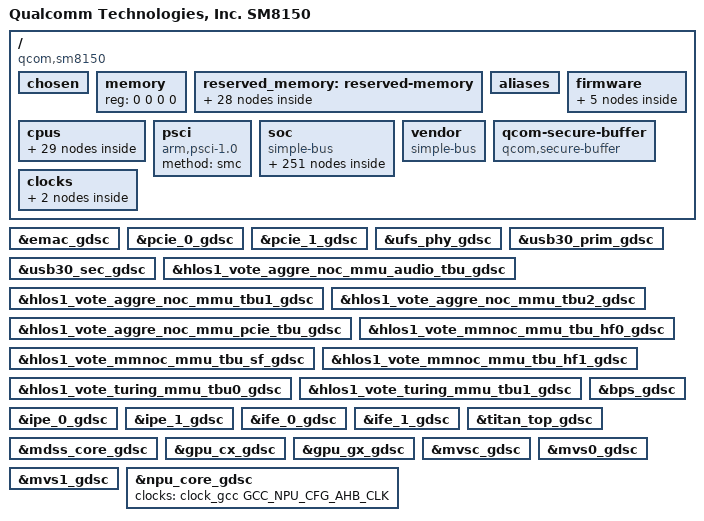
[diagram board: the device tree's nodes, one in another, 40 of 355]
// SPDX-License-Identifier: GPL-2.0-only
/*
 * Copyright (c) 2017-2020, The Linux Foundation. All rights reserved.
 */

#include <dt-bindings/clock/qcom,gcc-sm8150.h>
#include <dt-bindings/clock/qcom,camcc-sm8150.h>
#include <dt-bindings/clock/qcom,dispcc-sm8150.h>
#include <dt-bindings/clock/qcom,gpucc-sm8150.h>
#include <dt-bindings/clock/qcom,scc-sm8150.h>
#include <dt-bindings/clock/qcom,videocc-sm8150.h>
#include <dt-bindings/interconnect/qcom,icc.h>
#include <dt-bindings/interconnect/qcom,osm-l3.h>
#include <dt-bindings/interconnect/qcom,sm8150.h>
#include <dt-bindings/clock/qcom,npucc-sm8150.h>
#include <dt-bindings/gpio/gpio.h>
#include <dt-bindings/clock/qcom,rpmh.h>
#include <dt-bindings/sound/qcom,gpr.h>
#include <dt-bindings/clock/qcom,aop-qmp.h>
#include <dt-bindings/regulator/qcom,rpmh-regulator-levels.h>
#include <dt-bindings/interrupt-controller/arm-gic.h>
#include <dt-bindings/soc/qcom,rpmh-rsc.h>
#include <dt-bindings/soc/qcom,dcc_v2.h>
#include <dt-bindings/spmi/spmi.h>

#define MHZ_TO_MBPS(mhz, w) ((mhz * 1000000 * w) / (1024 * 1024))
#define BW_OPP_ENTRY(mhz, w) opp-mhz {opp-hz = /bits/ 64 <MHZ_TO_MBPS(mhz, w)>;}
#define BW_OPP_ENTRY_DDR(mhz, w, ddrtype) opp-mhz {\
				opp-hz = /bits/ 64 <MHZ_TO_MBPS(mhz, w)>;\
				opp-supported-hw = <ddrtype>;}

/ {
	model = "Qualcomm Technologies, Inc. SM8150";
	compatible = "qcom,sm8150";
	qcom,msm-name = "SM8150 V1";
	qcom,msm-id = <339 0x10000>;
	interrupt-parent = <&intc>;

	#address-cells = <2>;
	#size-cells = <2>;

	chosen: chosen {
		bootargs = "rcupdate.rcu_expedited=1 rcu_nocbs=0-7 cgroup.memory=nokmem,nosocket kpti=0 ssbd=force-off";
	};

	memory { device_type = "memory"; reg = <0 0 0 0>; };
	reserved_memory: reserved-memory { };

	aliases {
		ufshc1 = &ufshc_mem; /* Embedded UFS slot */
		sdhc2 = &sdhc_2; /* SDC2 SD card slot */
		pci-domain0 = &pcie0; /* PCIe0 domain */
		pci-domain1 = &pcie1; /* PCIe1 domain */
		mhi0 = &mhi_0;
		mhi1 = &mhi_1;
		mhi-netdev0 = &mhi_netdev_0;
		mhi-netdev2 = &mhi_netdev_2;
		serial0 = &qupv3_se12_2uart;
		hsuart0 = &qupv3_se13_4uart;
		hsuart1 = &qupv3_se4_2uart;
		spi0 = &qupv3_se3_spi;
		spi1 = &qupv3_se1_spi;
		i2c0 = &qupv3_se4_i2c;
	};

	firmware: firmware { };

	cpus {
		#address-cells = <2>;
		#size-cells = <0>;

		CPU0: cpu@0 {
			device_type = "cpu";
			compatible = "arm,armv8";
			reg = <0x0 0x0>;
			enable-method = "psci";
			qcom,freq-domain = <&cpufreq_hw 0 4>;
			capacity-dmips-mhz = <488>;
			dynamic-power-coefficient = <232>;
			cpu-idle-states = <&SLVR_RAIL_OFF>;
			next-level-cache = <&L2_0>;
			qcom,lmh-dcvs = <&lmh_dcvs0>;
			#cooling-cells = <2>;
			L2_0: l2-cache {
			      compatible = "arm,arch-cache";
			      cache-level = <2>;
			      next-level-cache = <&L3_0>;

				L3_0: l3-cache {
				      compatible = "arm,arch-cache";
				      cache-level = <3>;
				};
			};
		};

		CPU1: cpu@100 {
			device_type = "cpu";
			compatible = "arm,armv8";
			reg = <0x0 0x100>;
			enable-method = "psci";
			qcom,freq-domain = <&cpufreq_hw 0 4>;
			capacity-dmips-mhz = <488>;
			dynamic-power-coefficient = <232>;
			cpu-idle-states = <&SLVR_RAIL_OFF>;
			next-level-cache = <&L2_1>;
			qcom,lmh-dcvs = <&lmh_dcvs0>;
			#cooling-cells = <2>;
			L2_1: l2-cache {
			      compatible = "arm,arch-cache";
			      cache-level = <2>;
			      next-level-cache = <&L3_0>;
			};
		};

		CPU2: cpu@200 {
			device_type = "cpu";
			compatible = "arm,armv8";
			reg = <0x0 0x200>;
			enable-method = "psci";
			qcom,freq-domain = <&cpufreq_hw 0 4>;
			capacity-dmips-mhz = <488>;
			dynamic-power-coefficient = <232>;
			cpu-idle-states = <&SLVR_RAIL_OFF>;
			next-level-cache = <&L2_2>;
			qcom,lmh-dcvs = <&lmh_dcvs0>;
			#cooling-cells = <2>;
			L2_2: l2-cache {
			      compatible = "arm,arch-cache";
			      cache-level = <2>;
			      next-level-cache = <&L3_0>;
			};
		};

		CPU3: cpu@300 {
			device_type = "cpu";
			compatible = "arm,armv8";
			reg = <0x0 0x300>;
			enable-method = "psci";
			qcom,freq-domain = <&cpufreq_hw 0 4>;
			capacity-dmips-mhz = <488>;
			dynamic-power-coefficient = <232>;
			cpu-idle-states = <&SLVR_RAIL_OFF>;
			next-level-cache = <&L2_3>;
			qcom,lmh-dcvs = <&lmh_dcvs0>;
			#cooling-cells = <2>;
			L2_3: l2-cache {
			      compatible = "arm,arch-cache";
			      cache-level = <2>;
			      next-level-cache = <&L3_0>;
			};
		};

		CPU4: cpu@400 {
			device_type = "cpu";
			compatible = "arm,armv8";
			reg = <0x0 0x400>;
			enable-method = "psci";
			qcom,freq-domain = <&cpufreq_hw 1 4>;
			capacity-dmips-mhz = <1024>;
			dynamic-power-coefficient = <369>;
			cpu-idle-states = <&GOLD_RAIL_OFF>;
			next-level-cache = <&L2_4>;
			qcom,lmh-dcvs = <&lmh_dcvs1>;
			#cooling-cells = <2>;
			L2_4: l2-cache {
			      compatible = "arm,arch-cache";
			      cache-level = <2>;
			      next-level-cache = <&L3_0>;
			};
		};

		CPU5: cpu@500 {
			device_type = "cpu";
			compatible = "arm,armv8";
			reg = <0x0 0x500>;
			enable-method = "psci";
			qcom,freq-domain = <&cpufreq_hw 1 4>;
			capacity-dmips-mhz = <1024>;
			dynamic-power-coefficient = <369>;
			cpu-idle-states = <&GOLD_RAIL_OFF>;
			next-level-cache = <&L2_5>;
			qcom,lmh-dcvs = <&lmh_dcvs1>;
			#cooling-cells = <2>;
			L2_5: l2-cache {
			      compatible = "arm,arch-cache";
			      cache-level = <2>;
			      next-level-cache = <&L3_0>;
			};
		};

		CPU6: cpu@600 {
			device_type = "cpu";
			compatible = "arm,armv8";
			reg = <0x0 0x600>;
			enable-method = "psci";
			qcom,freq-domain = <&cpufreq_hw 1 4>;
			capacity-dmips-mhz = <1024>;
			dynamic-power-coefficient = <369>;
			cpu-idle-states = <&GOLD_RAIL_OFF>;
			next-level-cache = <&L2_6>;
			qcom,lmh-dcvs = <&lmh_dcvs1>;
			#cooling-cells = <2>;
			L2_6: l2-cache {
			      compatible = "arm,arch-cache";
			      cache-level = <2>;
			      next-level-cache = <&L3_0>;
			};
		};

		CPU7: cpu@700 {
			device_type = "cpu";
			compatible = "arm,armv8";
			reg = <0x0 0x700>;
			enable-method = "psci";
			qcom,freq-domain = <&cpufreq_hw 2 4>;
			capacity-dmips-mhz = <1024>;
			dynamic-power-coefficient = <421>;
			cpu-idle-states = <&GOLD_RAIL_OFF>;
			next-level-cache = <&L2_7>;
			qcom,lmh-dcvs = <&lmh_dcvs1>;
			#cooling-cells = <2>;
			L2_7: l2-cache {
			      compatible = "arm,arch-cache";
			      cache-level = <2>;
			      next-level-cache = <&L3_0>;
			};
		};

		cpu-map {
			cluster0 {
				core0 {
					cpu = <&CPU0>;
				};

				core1 {
					cpu = <&CPU1>;
				};

				core2 {
					cpu = <&CPU2>;
				};

				core3 {
					cpu = <&CPU3>;
				};
			};

			cluster1 {
				core0 {
					cpu = <&CPU4>;
				};

				core1 {
					cpu = <&CPU5>;
				};

				core2 {
					cpu = <&CPU6>;
				};
			};

			cluster2 {
				core0 {
					cpu = <&CPU7>;
				};
			};
		};
	};

	psci {
		compatible = "arm,psci-1.0";
		method = "smc";
	};

	soc: soc { };

	vendor: vendor {
		#address-cells = <1>;
		#size-cells = <1>;
		ranges = <0 0 0 0xffffffff>;
		compatible = "simple-bus";
	};

	qcom-secure-buffer {
		compatible = "qcom,secure-buffer";
	};

	clocks {
		xo_board: xo-board {
			compatible = "fixed-clock";
			clock-frequency = <38400000>;
			clock-output-names = "xo_board";
			#clock-cells = <0>;
		};

		sleep_clk: sleep-clk {
			compatible = "fixed-clock";
			clock-frequency = <32764>;
			clock-output-names = "sleep_clk";
			#clock-cells = <0>;
		};
	};
};

&firmware {
	scm {
		compatible = "qcom,scm";
	};
	android {
		compatible = "android,firmware";
		shared_meta: vbmeta {
			compatible = "android,vbmeta";
			parts = "vbmeta,boot,system,vendor,dtbo";
		};
		android_q_fstab: fstab {
			compatible = "android,fstab";
			vendor {
				compatible = "android,vendor";
				dev = "/dev/block/platform/soc/8804000.ufshc/by-name/vendor";
				type = "ext4";
				mnt_flags = "ro,barrier=1,discard";
				fsmgr_flags = "wait";
				status = "ok";
			};
		};
	};
};

&reserved_memory {
	#address-cells = <2>;
	#size-cells = <2>;
	ranges;

	hyp_mem: hyp_mem {
		no-map;
		reg = <0x0 0x85700000 0x0 0x600000>;
	};

	xbl_aop_mem: xbl_aop_mem {
		no-map;
		reg = <0x0 0x85e00000 0x0 0x120000>;
	};

	cmd_db: reserved-memory@85f20000 {
		compatible = "qcom,cmd-db";
		reg = <0x0 0x85f20000 0x0 0x20000>;
		no-map;
	};

	smem_region: smem {
		no-map;
		reg = <0x0 0x86000000 0x0 0x200000>;
	};

	removed_regions: removed_regions {
		no-map;
		reg = <0x0 0x86200000 0x0 0x5500000>;
	};

	pil_camera_mem: camera_region {
		compatible = "removed-dma-pool";
		no-map;
		reg = <0x0 0x8b700000 0x0 0x500000>;
	};

	pil_wlan_fw_mem: pil_wlan_fw_region {
		compatible = "removed-dma-pool";
		no-map;
		reg = <0x0 0x8bc00000 0x0 0x180000>;
	};

	pil_npu_mem: pil_npu_region {
		compatible = "removed-dma-pool";
		no-map;
		reg = <0x0 0x8bd80000 0x0 0x80000>;
	};

	pil_adsp_mem: pil_adsp_region {
		compatible = "removed-dma-pool";
		no-map;
		reg = <0x0 0x8be00000 0x0 0x2200000>;
	};

	pil_modem_mem: modem_region {
		compatible = "removed-dma-pool";
		no-map;
		reg = <0x0 0x8e000000 0x0 0x9600000>;
	};

	pil_video_mem: pil_video_region {
		compatible = "removed-dma-pool";
		no-map;
		reg = <0x0 0x97600000 0x0 0x500000>;
	};

	pil_slpi_mem: pil_slpi_region {
		compatible = "removed-dma-pool";
		no-map;
		reg = <0x0 0x97b00000 0x0 0x1400000>;
	};

	pil_ipa_fw_mem: pil_ipa_fw_region {
		compatible = "removed-dma-pool";
		no-map;
		reg = <0x0 0x98f00000 0x0 0x10000>;
	};

	pil_ipa_gsi_mem: pil_ipa_gsi_region {
		compatible = "removed-dma-pool";
		no-map;
		reg = <0x0 0x98f10000 0x0 0x5000>;
	};

	pil_gpu_mem: pil_gpu_region {
		compatible = "removed-dma-pool";
		no-map;
		reg = <0x0 0x98f15000 0x0 0x2000>;
	};

	pil_spss_mem: pil_spss_region {
		compatible = "removed-dma-pool";
		no-map;
		reg = <0x0 0x99000000 0x0 0x100000>;
	};

	pil_cdsp_mem: cdsp_regions {
		compatible = "removed-dma-pool";
		no-map;
		reg = <0x0 0x99100000 0x0 0x1400000>;
	};

	qseecom_mem: qseecom_region {
		compatible = "shared-dma-pool";
		no-map;
		reg = <0 0x9e400000 0 0x1400000>;
	};

	cdsp_sec_mem: cdsp_sec_regions {
		compatible = "removed-dma-pool";
		no-map;
		reg = <0x0 0xa4c00000 0x0 0x3c00000>;
	};

	cont_splash_memory: splash_region {
		reg = <0x0 0x9c000000 0x0 0x02400000>;
		label = "cont_splash_region";
	};

	dfps_data_memory: dfps_data_memory {
		reg = <0x0 0xe3300000 0x0 0x0100000>;
		label = "dfps_data_memory";
	};

	adsp_mem: adsp_region {
		compatible = "shared-dma-pool";
		alloc-ranges = <0x0 0x00000000 0x0 0xffffffff>;
		reusable;
		alignment = <0x0 0x400000>;
		size = <0x0 0x1000000>;
	};

	cdsp_mem: cdsp_region {
		compatible = "shared-dma-pool";
		alloc-ranges = <0x0 0x00000000 0x0 0xffffffff>;
		reusable;
		alignment = <0x0 0x400000>;
		size = <0x0 0x400000>;
	};

	user_contig_mem: user_contig_region {
		compatible = "shared-dma-pool";
		alloc-ranges = <0x0 0x00000000 0x0 0xffffffff>;
		reusable;
		alignment = <0x0 0x400000>;
		size = <0x0 0x1000000>;
	};

	qseecom_ta_mem: qseecom_ta_region {
		compatible = "shared-dma-pool";
		alloc-ranges = <0x0 0x00000000 0x0 0xffffffff>;
		reusable;
		alignment = <0x0 0x400000>;
		size = <0x0 0x1000000>;
	};

	sp_mem: sp_region {  /* SPSS-HLOS ION shared mem */
		compatible = "shared-dma-pool";
		alloc-ranges = <0x0 0x00000000 0x0 0xffffffff>;
		reusable;
		alignment = <0x0 0x400000>;
		size = <0x0 0x800000>;
	};

	secure_display_memory: secure_display_region { /* Secure UI */
		compatible = "shared-dma-pool";
		alloc-ranges = <0x0 0x00000000 0x0 0xffffffff>;
		reusable;
		alignment = <0x0 0x400000>;
		size = <0x0 0xA000000>;
	};

	/* global autoconfigured region for contiguous allocations */
	linux,cma {
		compatible = "shared-dma-pool";
		alloc-ranges = <0x0 0x00000000 0x0 0xffffffff>;
		reusable;
		alignment = <0x0 0x400000>;
		size = <0x0 0x2800000>;
		linux,cma-default;
	};
};

#include "sm8150-gdsc.dtsi"

#include "sm8150-sde.dtsi"
#include "msm-rdbg.dtsi"

#include "sm8150-camera.dtsi"

#include "msm-qvr-external.dtsi"

&soc {
	#address-cells = <1>;
	#size-cells = <1>;
	ranges = <0 0 0 0xffffffff>;
	compatible = "simple-bus";

	spss_utils: qcom,spss_utils {
		compatible = "qcom,spss-utils";
		/* spss fuses physical address */
		qcom,spss-fuse1-addr = <0x007841c4>;
		qcom,spss-fuse1-bit = <27>;
		qcom,spss-fuse2-addr = <0x007841c4>;
		qcom,spss-fuse2-bit = <26>;
		qcom,spss-dev-firmware-name  = "spss1d";  /* 8 chars max */
		qcom,spss-test-firmware-name = "spss1t";  /* 8 chars max */
		qcom,spss-prod-firmware-name = "spss1p";  /* 8 chars max */
		qcom,spss-debug-reg-addr = <0x01886020>;
		qcom,spss-emul-type-reg-addr = <0x01fc8004>;
		qcom,no-cmac-and-iar-feature-support;
		status = "ok";
	};

	qcom,spcom {
		compatible = "qcom,spcom";

		/* predefined channels, remote side is server */
		qcom,spcom-ch-names = "sp_kernel", "sp_ssr";
		status = "ok";
	};

	jtag_mm0: jtagmm@7040000 {
		compatible = "qcom,jtagv8-mm";
		reg = <0x7040000 0x1000>;
		reg-names = "etm-base";

		clocks = <&clock_aop QDSS_CLK>;
		clock-names = "core_clk";

		qcom,coresight-jtagmm-cpu = <&CPU0>;
		status = "disabled";
	};

	jtag_mm1: jtagmm@7140000 {
		compatible = "qcom,jtagv8-mm";
		reg = <0x7140000 0x1000>;
		reg-names = "etm-base";

		clocks = <&clock_aop QDSS_CLK>;
		clock-names = "core_clk";

		qcom,coresight-jtagmm-cpu = <&CPU1>;
		status = "disabled";
	};

	jtag_mm2: jtagmm@7240000 {
		compatible = "qcom,jtagv8-mm";
		reg = <0x7240000 0x1000>;
		reg-names = "etm-base";

		clocks = <&clock_aop QDSS_CLK>;
		clock-names = "core_clk";

		qcom,coresight-jtagmm-cpu = <&CPU2>;
		status = "disabled";
	};

	jtag_mm3: jtagmm@7340000 {
		compatible = "qcom,jtagv8-mm";
		reg = <0x7340000 0x1000>;
		reg-names = "etm-base";

		clocks = <&clock_aop QDSS_CLK>;
		clock-names = "core_clk";

		qcom,coresight-jtagmm-cpu = <&CPU3>;
		status = "disabled";
	};

	jtag_mm4: jtagmm@7440000 {
		compatible = "qcom,jtagv8-mm";
		reg = <0x7440000 0x1000>;
		reg-names = "etm-base";

		clocks = <&clock_aop QDSS_CLK>;
		clock-names = "core_clk";

		qcom,coresight-jtagmm-cpu = <&CPU4>;
		status = "disabled";
	};

	jtag_mm5: jtagmm@7540000 {
		compatible = "qcom,jtagv8-mm";
		reg = <0x7540000 0x1000>;
		reg-names = "etm-base";

		clocks = <&clock_aop QDSS_CLK>;
		clock-names = "core_clk";

		qcom,coresight-jtagmm-cpu = <&CPU5>;
		status = "disabled";
	};

	jtag_mm6: jtagmm@7640000 {
		compatible = "qcom,jtagv8-mm";
		reg = <0x7640000 0x1000>;
		reg-names = "etm-base";

		clocks = <&clock_aop QDSS_CLK>;
		clock-names = "core_clk";

		qcom,coresight-jtagmm-cpu = <&CPU6>;
		status = "disabled";
	};

	jtag_mm7: jtagmm@7740000 {
		compatible = "qcom,jtagv8-mm";
		reg = <0x7740000 0x1000>;
		reg-names = "etm-base";

		clocks = <&clock_aop QDSS_CLK>;
		clock-names = "core_clk";

		qcom,coresight-jtagmm-cpu = <&CPU7>;
		status = "disabled";
	};

	intc: interrupt-controller@17a00000 {
		compatible = "arm,gic-v3";
		#interrupt-cells = <3>;
		interrupt-controller;
		#redistributor-regions = <1>;
		redistributor-stride = <0x0 0x20000>;
		reg = <0x17a00000 0x10000>,     /* GICD */
		      <0x17a60000 0x100000>;    /* GICR * 8 */
		interrupts = <GIC_PPI 9 IRQ_TYPE_LEVEL_HIGH>;
		interrupt-parent = <&intc>;
	};

	gict: gict@17a20000 {
		compatible = "arm,gic-600-erp";
		reg = <0x17a20000 0x10000>;
		reg-names = "gict-base";
		interrupt-config = <46 17>;
		interrupt-names = "gict-fault", "gict-err";
		interrupts = <GIC_SPI 46 IRQ_TYPE_LEVEL_HIGH>,
			     <GIC_SPI 17 IRQ_TYPE_LEVEL_HIGH>;
	};

	pdc: interrupt-controller@b220000 {
		compatible = "qcom,sm8150-pdc";
		reg = <0xb220000 0x400>;
		qcom,pdc-ranges = <0 480 94>, <94 609 31>, <125 63 1>;
		#interrupt-cells = <2>;
		interrupt-parent = <&intc>;
		interrupt-controller;
	};

	timer {
		compatible = "arm,armv8-timer";
		interrupts = <GIC_PPI 1 (GIC_CPU_MASK_SIMPLE(8) | IRQ_TYPE_LEVEL_LOW)>,
			     <GIC_PPI 2 (GIC_CPU_MASK_SIMPLE(8) | IRQ_TYPE_LEVEL_LOW)>,
			     <GIC_PPI 3 (GIC_CPU_MASK_SIMPLE(8) | IRQ_TYPE_LEVEL_LOW)>,
			     <GIC_PPI 0 (GIC_CPU_MASK_SIMPLE(8) | IRQ_TYPE_LEVEL_LOW)>;
		clock-frequency = <19200000>;
	};

	timer@17c20000{
		#address-cells = <1>;
		#size-cells = <1>;
		ranges;
		compatible = "arm,armv7-timer-mem";
		reg = <0x17c20000 0x1000>;
		clock-frequency = <19200000>;

		frame@17c21000 {
			frame-number = <0>;
			interrupts = <GIC_SPI 8 IRQ_TYPE_LEVEL_HIGH>,
				     <GIC_SPI 6 IRQ_TYPE_LEVEL_HIGH>;
			reg = <0x17c21000 0x1000>,
			      <0x17c22000 0x1000>;
		};

		frame@17c23000 {
			frame-number = <1>;
			interrupts = <GIC_SPI 9 IRQ_TYPE_LEVEL_HIGH>;
			reg = <0x17c23000 0x1000>;
			status = "disabled";
		};

		frame@17c25000 {
			frame-number = <2>;
			interrupts = <GIC_SPI 10 IRQ_TYPE_LEVEL_HIGH>;
			reg = <0x17c25000 0x1000>;
			status = "disabled";
		};

		frame@17c27000 {
			frame-number = <3>;
			interrupts = <GIC_SPI 11 IRQ_TYPE_LEVEL_HIGH>;
			reg = <0x17c26000 0x1000>;
			status = "disabled";
		};

		frame@17c29000 {
			frame-number = <4>;
			interrupts = <GIC_SPI 12 IRQ_TYPE_LEVEL_HIGH>;
			reg = <0x17c29000 0x1000>;
			status = "disabled";
		};

		frame@17c2b000 {
			frame-number = <5>;
			interrupts = <GIC_SPI 13 IRQ_TYPE_LEVEL_HIGH>;
			reg = <0x17c2b000 0x1000>;
			status = "disabled";
		};

		frame@17c2d000 {
			frame-number = <6>;
			interrupts = <GIC_SPI 14 IRQ_TYPE_LEVEL_HIGH>;
			reg = <0x17c2d000 0x1000>;
			status = "disabled";
		};
	};

	llcc_pmu: llcc-pmu@90cc000 {
		compatible = "qcom,llcc-pmu-ver1";
		reg = <0x090cc000 0x300>;
		reg-names = "lagg-base";
	};

	llcc_bw_opp_table: llcc-bw-opp-table {
		compatible = "operating-points-v2";
		BW_OPP_ENTRY(150, 16); /*  2288 MB/s */
		BW_OPP_ENTRY(200, 16); /*  3051 MB/s */
		BW_OPP_ENTRY(403, 16); /*  6149 MB/s */
		BW_OPP_ENTRY(533, 16); /*  8132 MB/s */
		BW_OPP_ENTRY(666, 16); /* 10162 MB/s */
		BW_OPP_ENTRY(777, 16); /* 11856 MB/s */
	};

	ddr_bw_opp_table: ddr-bw-opp-table {
		compatible = "operating-points-v2";
		BW_OPP_ENTRY_DDR( 200, 4, 0x80); /*  762 MB/s */
		BW_OPP_ENTRY_DDR( 300, 4, 0x80); /* 1144 MB/s */
		BW_OPP_ENTRY_DDR( 451, 4, 0x80); /* 1720 MB/s */
		BW_OPP_ENTRY_DDR( 547, 4, 0x80); /* 2086 MB/s */
		BW_OPP_ENTRY_DDR( 681, 4, 0x80); /* 2597 MB/s */
		BW_OPP_ENTRY_DDR( 768, 4, 0x80); /* 2929 MB/s */
		BW_OPP_ENTRY_DDR(1017, 4, 0x80); /* 3879 MB/s */
		BW_OPP_ENTRY_DDR(1296, 4, 0x80); /* 4943 MB/s */
		BW_OPP_ENTRY_DDR(1555, 4, 0x80); /* 5931 MB/s */
		BW_OPP_ENTRY_DDR(1804, 4, 0x80); /* 6881 MB/s */
		BW_OPP_ENTRY_DDR(2092, 4, 0x80); /* 7980 MB/s */
	};

	cpu_cpu_llcc_bw: qcom,cpu-cpu-llcc-bw {
		compatible = "qcom,devfreq-icc";
		governor = "bw_hwmon";
		interconnects = <&gem_noc MASTER_APPSS_PROC
				&gem_noc SLAVE_LLCC>;
		qcom,active-only;
		operating-points-v2 = <&llcc_bw_opp_table>;
	};

	cpu_cpu_llcc_bwmon: qcom,cpu-cpu-llcc-bwmon@90b6400 {
		compatible = "qcom,bimc-bwmon4";
		reg = <0x90b6400 0x300>, <0x90b6300 0x200>;
		reg-names = "base", "global_base";
		interrupts = <GIC_SPI 581 IRQ_TYPE_LEVEL_HIGH>;
		qcom,mport = <0>;
		qcom,hw-timer-hz = <19200000>;
		qcom,target-dev = <&cpu_cpu_llcc_bw>;
		qcom,count-unit = <0x10000>;
	};

	cpu_llcc_ddr_bw: qcom,cpu-llcc-ddr-bw {
		compatible = "qcom,devfreq-icc-ddr";
		governor = "bw_hwmon";
		interconnects = <&mc_virt MASTER_LLCC &mc_virt SLAVE_EBI1>;
		qcom,active-only;
		operating-points-v2 = <&ddr_bw_opp_table>;
	};

	cpu_llcc_ddr_bwmon: qcom,cpu-llcc-ddr-bwmon@90cd000 {
		compatible = "qcom,bimc-bwmon5";
		reg = <0x90cd000 0x1000>;
		reg-names = "base";
		interrupts = <GIC_SPI 81 IRQ_TYPE_LEVEL_HIGH>;
		qcom,hw-timer-hz = <19200000>;
		qcom,target-dev = <&cpu_llcc_ddr_bw>;
		qcom,count-unit = <0x10000>;
	};

	cpu0_cpu_l3_lat: qcom,cpu0-cpu-l3-lat {
		compatible = "qcom,devfreq-icc-l3";
		reg = <0x18321110 0x500>;
		reg-names = "ftbl-base";
		qcom,ftbl-row-size = <0x20>;
		governor = "mem_latency";
		interconnects = <&osm_l3 MASTER_OSM_L3_APPS
				&osm_l3 SLAVE_OSM_L3_CLUSTER0>;
	};

	cpu0_cpu_l3_tbl: qcom,cpu0-cpu-l3-tbl {
		qcom,core-dev-table =
			<  300000  300000000 >,
			<  480000  403200000 >,
			<  672000  480000000 >,
			<  768000  576000000 >,
			<  864000  672000000 >,
			<  979200  768000000 >,
			< 1075200  864000000 >,
			< 1267200  960000000 >;
	};

	cpu0_cpu_llcc_lat: qcom,cpu0-cpu-llcc-lat {
		compatible = "qcom,devfreq-icc";
		governor = "mem_latency";
		interconnects = <&gem_noc MASTER_APPSS_PROC
				&gem_noc SLAVE_LLCC>;
		qcom,active-only;
		operating-points-v2 = <&llcc_bw_opp_table>;
	};

	cpu0_llcc_ddr_lat: qcom,cpu0-llcc-ddr-lat {
		compatible = "qcom,devfreq-icc-ddr";
		governor = "mem_latency";
		interconnects = <&mc_virt MASTER_LLCC &mc_virt SLAVE_EBI1>;
		qcom,active-only;
		operating-points-v2 = <&ddr_bw_opp_table>;
	};

	cpu0_memlat_cpugrp: qcom,cpu0-cpugrp {
		compatible = "qcom,arm-memlat-cpugrp";
		qcom,cpulist = <&CPU0 &CPU1 &CPU2 &CPU3>;

		cpu0_cpu_l3_latmon: qcom,cpu0-cpu-l3-latmon {
			compatible = "qcom,arm-memlat-mon";
			qcom,cpulist = <&CPU0 &CPU1 &CPU2 &CPU3>;
			qcom,target-dev = <&cpu0_cpu_l3_lat>;
			qcom,cachemiss-ev = <0x17>;
			qcom,core-dev-table = <&cpu0_cpu_l3_tbl>;
		};

		cpu0_cpu_llcc_latmon: qcom,cpu0-cpu-llcc-latmon {
			compatible = "qcom,arm-memlat-mon";
			qcom,cpulist = <&CPU0 &CPU1 &CPU2 &CPU3>;
			qcom,target-dev = <&cpu0_cpu_llcc_lat>;
			qcom,cachemiss-ev = <0x2A>;
			qcom,core-dev-table =
				<  300000 MHZ_TO_MBPS(150, 16) >,
				<  768000 MHZ_TO_MBPS(200, 16) >,
				< 1075200 MHZ_TO_MBPS(403, 16) >,
				< 1267200 MHZ_TO_MBPS(403, 16) >;
		};

		cpu0_llcc_ddr_latmon: qcom,cpu0-llcc-ddr-latmon {
			compatible = "qcom,arm-memlat-mon";
			qcom,cpulist = <&CPU0 &CPU1 &CPU2 &CPU3>;
			qcom,target-dev = <&cpu0_llcc_ddr_lat>;
			qcom,cachemiss-ev = <0x1000>;
			qcom,core-dev-table =
				<  300000 MHZ_TO_MBPS( 200, 4) >,
				<  768000 MHZ_TO_MBPS( 451, 4) >,
				< 1075200 MHZ_TO_MBPS( 547, 4) >,
				< 1267200 MHZ_TO_MBPS( 768, 4) >;
		};
	};

	cpu4_cpu_l3_lat: qcom,cpu4-cpu-l3-lat {
		compatible = "qcom,devfreq-icc-l3";
		reg = <0x18321110 0x500>;
		reg-names = "ftbl-base";
		qcom,ftbl-row-size = <0x20>;
		governor = "mem_latency";
		interconnects = <&osm_l3 MASTER_OSM_L3_APPS
				&osm_l3 SLAVE_OSM_L3_CLUSTER1>;
	};

	cpu4_cpu_l3_tbl: qcom,cpu4_cpu_l3_tbl {
		qcom,core-dev-table =
			<  300000  300000000 >,
			<  768000  576000000 >,
			< 1152000  768000000 >,
			< 1344000  960000000 >,
			< 1689600 1228800000 >,
			< 2016000 1344000000 >;
	};

	cpu4_cpu_llcc_lat: qcom,cpu4-cpu-llcc-lat {
		compatible = "qcom,devfreq-icc";
		governor = "mem_latency";
		interconnects = <&gem_noc MASTER_APPSS_PROC
				&gem_noc SLAVE_LLCC>;
		qcom,active-only;
		operating-points-v2 = <&llcc_bw_opp_table>;
	};

	cpu4_llcc_ddr_lat: qcom,cpu4-llcc-ddr-lat {
		compatible = "qcom,devfreq-icc-ddr";
		governor = "mem_latency";
		interconnects = <&mc_virt MASTER_LLCC &mc_virt SLAVE_EBI1>;
		qcom,active-only;
		operating-points-v2 = <&ddr_bw_opp_table>;
	};

	cpu4_cpu_ddr_latfloor: qcom,cpu4-cpu-ddr-latfloor {
		compatible = "qcom,devfreq-icc-ddr";
		governor = "compute";
		interconnects = <&mc_virt MASTER_LLCC &mc_virt SLAVE_EBI1>;
		qcom,active-only;
		operating-points-v2 = <&ddr_bw_opp_table>;
	};

	cdsp_cdsp_l3_lat: qcom,cdsp-cdsp-l3-lat {
		compatible = "qcom,devfreq-icc-l3";
		reg = <0x18321920 0x4>;
		reg-names = "perf-base";
		qcom,ftbl-row-size = <0x20>;
		governor = "powersave";
		interconnects = <&osm_l3 MASTER_OSM_L3_APPS
				&osm_l3 SLAVE_OSM_L3_MISC>;
	};

	cpu7_cpu_l3_lat: qcom,cpu7-cpu-l3-lat {
		compatible = "qcom,devfreq-icc-l3";
		reg = <0x18321110 0x500>;
		reg-names = "ftbl-base";
		qcom,ftbl-row-size = <0x20>;
		governor = "compute";
		interconnects = <&osm_l3 MASTER_OSM_L3_APPS
				&osm_l3 SLAVE_OSM_L3_CLUSTER2>;
	};

	cpu7_cpu_l3_tbl: qcom,cpu7_cpu_l3_tbl {
		qcom,core-dev-table =
			<  300000  300000000 >,
			<  768000  576000000 >,
			< 1152000  768000000 >,
			< 1344000  960000000 >,
			< 1689600 1228800000 >,
			< 2016000 1344000000 >;
	};

	cpu4_memlat_cpugrp: qcom,cpu4-cpugrp {
		compatible = "qcom,arm-memlat-cpugrp";
		qcom,cpulist = <&CPU4 &CPU5 &CPU6 &CPU7>;

		cpu4_cpu_l3_latmon: qcom,cpu4-cpu-l3-latmon {
			compatible = "qcom,arm-memlat-mon";
			qcom,cpulist = <&CPU4 &CPU5 &CPU6>;
			qcom,target-dev = <&cpu4_cpu_l3_lat>;
			qcom,cachemiss-ev = <0x17>;
			qcom,core-dev-table = <&cpu4_cpu_l3_tbl>;
		};

		cpu7_cpu_l3_latmon: qcom,cpu7-cpu-l3-latmon {
			compatible = "qcom,arm-memlat-mon";
			qcom,cpulist = <&CPU7>;
			qcom,target-dev = <&cpu7_cpu_l3_lat>;
			qcom,cachemiss-ev = <0x17>;
			qcom,core-dev-table = <&cpu7_cpu_l3_tbl>;
		};

		cpu4_cpu_llcc_latmon: qcom,cpu4-cpu-llcc-latmon {
			compatible = "qcom,arm-memlat-mon";
			qcom,cpulist = <&CPU4 &CPU5 &CPU6 &CPU7>;
			qcom,target-dev = <&cpu4_cpu_llcc_lat>;
			qcom,cachemiss-ev = <0x2A>;
			qcom,core-dev-table =
				<  300000 MHZ_TO_MBPS(150, 16) >,
				<  576000 MHZ_TO_MBPS(200, 16) >,
				<  768000 MHZ_TO_MBPS(403, 16) >,
				<  960000 MHZ_TO_MBPS(403, 16) >,
				< 1248000 MHZ_TO_MBPS(533, 16) >,
				< 1728000 MHZ_TO_MBPS(666, 16) >,
				< 2016000 MHZ_TO_MBPS(777, 16) >;
		};

		cpu4_llcc_ddr_latmon: qcom,cpu4-llcc-ddr-latmon {
			compatible = "qcom,arm-memlat-mon";
			qcom,cpulist = <&CPU4 &CPU5 &CPU6 &CPU7>;
			qcom,target-dev = <&cpu4_llcc_ddr_lat>;
			qcom,cachemiss-ev = <0x1000>;
			qcom,core-dev-table =
				<  300000 MHZ_TO_MBPS( 200, 4) >,
				<  576000 MHZ_TO_MBPS( 451, 4) >,
				<  768000 MHZ_TO_MBPS( 547, 4) >,
				<  960000 MHZ_TO_MBPS( 768, 4) >,
				< 1248000 MHZ_TO_MBPS(1017, 4) >,
				< 1728000 MHZ_TO_MBPS(1555, 4) >,
				< 2016000 MHZ_TO_MBPS(1804, 4) >,
				< 2054400 MHZ_TO_MBPS(2092, 4) >;
		};

		cpu4_computemon: qcom,cpu4-computemon {
			compatible = "qcom,arm-compute-mon";
			qcom,cpulist = <&CPU4 &CPU5 &CPU6 &CPU7>;
			qcom,target-dev = <&cpu4_cpu_ddr_latfloor>;
			qcom,core-dev-table =
				< 1593600 MHZ_TO_MBPS( 200, 4) >,
				< 2016000 MHZ_TO_MBPS(1017, 4) >,
				< 2054400 MHZ_TO_MBPS(2092, 4) >;
		};
	};

	npu_npu_ddr_bw: qcom,npu-npu-ddr-bw {
		compatible = "qcom,devfreq-icc-ddr";
		governor = "bw_hwmon";
		interconnects = <&compute_noc MASTER_NPU &mc_virt SLAVE_EBI1>;
		operating-points-v2 = <&ddr_bw_opp_table>;
	};

	npu_npu_ddr_bwmon: qcom,npu-npu-ddr-bwmon@9960300 {
		compatible = "qcom,bimc-bwmon4";
		reg = <0x9960300 0x300>, <0x9960200 0x200>;
		reg-names = "base", "global_base";
		interrupts = <GIC_SPI 365 IRQ_TYPE_LEVEL_HIGH>;
		qcom,mport = <0>;
		qcom,hw-timer-hz = <19200000>;
		qcom,target-dev = <&npu_npu_ddr_bw>;
		qcom,count-unit = <0x10000>;
	};

	cpu_pmu: cpu-pmu {
		compatible = "arm,armv8-pmuv3";
		qcom,irq-is-percpu;
		interrupts = <GIC_PPI 5 IRQ_TYPE_LEVEL_HIGH>;
	};

	qcom,msm-imem@146bf000 {
		compatible = "qcom,msm-imem";
		reg = <0x146bf000 0x1000>;
		ranges = <0x0 0x146bf000 0x1000>;
		#address-cells = <1>;
		#size-cells = <1>;

		mem_dump_table@10 {
			compatible = "qcom,msm-imem-mem_dump_table";
			reg = <0x10 8>;
		};

		restart_reason@65c {
			compatible = "qcom,msm-imem-restart_reason";
			reg = <0x65c 4>;
		};

		dload_type@1c {
			compatible = "qcom,msm-imem-dload-type";
			reg = <0x1c 0x4>;
		};

		boot_stats@6b0 {
			compatible = "qcom,msm-imem-boot_stats";
			reg = <0x6b0 32>;
		};

		kaslr_offset@6d0 {
			compatible = "qcom,msm-imem-kaslr_offset";
			reg = <0x6d0 12>;
		};

		pil@94c {
			compatible = "qcom,msm-imem-pil";
			reg = <0x94c 200>;
		};

		diag_dload@c8 {
			compatible = "qcom,msm-imem-diag-dload";
			reg = <0xc8 200>;
		};
	};

	restart@c264000 {
		compatible = "qcom,pshold";
		reg = <0xc264000 0x4>,
		      <0x1fd3000 0x4>;
		reg-names = "pshold-base", "tcsr-boot-misc-detect";
	};

	qcom,msm-rtb {
		compatible = "qcom,msm-rtb";
		qcom,rtb-size = <0x100000>;
	};

	pil_scm_pas {
		compatible = "qcom,pil-tz-scm-pas";
		interconnects = <&aggre2_noc MASTER_CRYPTO
				&mc_virt SLAVE_EBI1>;
	};

	qcom,aop-ddr-msgs {
		compatible = "qcom,aop-ddr-msgs";
		mboxes = <&qmp_aop 0>;
		mbox-name = "restart-ddr-mbox";
	};

	qcom,aop-ddrss-cmds {
		compatible = "qcom,aop-ddrss-cmds";
		mboxes = <&qmp_aop 0>;
		mbox-name = "ddrss-cmds-mbox";
	};

	qcom,mpm2-sleep-counter@c221000 {
		compatible = "qcom,mpm2-sleep-counter";
		reg = <0xc221000 0x1000>;
		clock-frequency = <32768>;
	};

	clock_aop: qcom,aopclk {
		compatible = "qcom,aop-qmp-clk";
		#clock-cells = <1>;
		mboxes = <&qmp_aop 0>;
		mbox-names = "qdss_clk";
	};

	clock_gcc: qcom,gcc {
		compatible = "qcom,gcc-sm8150", "syscon";
		reg = <0x100000 0x1f0000>;
		reg-names = "cc_base";
		vdd_cx-supply = <&VDD_CX_LEVEL>;
		vdd_cx_ao-supply = <&VDD_CX_LEVEL_AO>;
		vdd_mm-supply = <&VDD_MMCX_LEVEL>;
		#clock-cells = <1>;
		#reset-cells = <1>;
	};

	clock_videocc: qcom,videocc@ab00000 {
		compatible = "qcom,videocc-sm8150", "syscon";
		reg = <0xab00000 0x10000>;
		reg-names = "cc_base";
		vdd_mm-supply = <&VDD_MMCX_LEVEL>;
		clock-names = "cfg_ahb_clk";
		clocks = <&clock_gcc GCC_VIDEO_AHB_CLK>;
		#clock-cells = <1>;
		#reset-cells = <1>;
	};

	clock_camcc: qcom,camcc {
		compatible = "qcom,camcc-sm8150", "syscon";
		reg = <0xad00000 0x10000>;
		reg-names = "cc_base";
		vdd_mx-supply = <&VDD_MX_LEVEL>;
		vdd_mm-supply = <&VDD_MMCX_LEVEL>;
		clock-names = "cfg_ahb_clk";
		clocks = <&clock_gcc GCC_CAMERA_AHB_CLK>;

		qcom,cam_cc_csi0phytimer_clk_src-opp-handle = <&cam_csiphy0>;
		qcom,cam_cc_csi1phytimer_clk_src-opp-handle = <&cam_csiphy1>;
		qcom,cam_cc_csi2phytimer_clk_src-opp-handle = <&cam_csiphy2>;
		qcom,cam_cc_csi3phytimer_clk_src-opp-handle = <&cam_csiphy3>;
		qcom,cam_cc_cci_0_clk_src-opp-handle = <&cam_cci0>;
		qcom,cam_cc_cci_1_clk_src-opp-handle = <&cam_cci1>;
		qcom,cam_cc_ife_0_csid_clk_src-opp-handle = <&cam_csid0>;
		qcom,cam_cc_ife_0_clk_src-opp-handle = <&cam_vfe0>;
		qcom,cam_cc_ife_1_csid_clk_src-opp-handle = <&cam_csid1>;
		qcom,cam_cc_ife_1_clk_src-opp-handle = <&cam_vfe1>;
		qcom,cam_cc_ife_lite_0_csid_clk_src-opp-handle =
							<&cam_csid_lite0>;
		qcom,cam_cc_ife_lite_1_csid_clk_src-opp-handle =
							<&cam_csid_lite1>;
		qcom,cam_cc_ife_lite_0_clk_src-opp-handle = <&cam_vfe_lite0>;
		qcom,cam_cc_ife_lite_1_clk_src-opp-handle = <&cam_vfe_lite1>;
		qcom,cam_cc_icp_clk_src-opp-handle = <&cam_a5>;
		qcom,cam_cc_ipe_0_clk_src-opp-handle = <&cam_ipe0>;
		qcom,cam_cc_bps_clk_src-opp-handle = <&cam_bps>;

		#clock-cells = <1>;
	};

	clock_dispcc: qcom,dispcc {
		compatible = "qcom,dispcc-sm8150", "syscon";
		reg = <0xaf00000 0x20000>;
		reg-names = "cc_base";
		vdd_mm-supply = <&VDD_MMCX_LEVEL>;
		clock-names = "cfg_ahb_clk";
		clocks = <&clock_gcc GCC_DISP_AHB_CLK>;
		#clock-cells = <1>;
		#reset-cells = <1>;
	};

	clock_npucc: qcom,npucc {
		compatible = "qcom,npucc-sm8150", "syscon";
		reg = <0x9910000 0x10000>;
		reg-names = "cc_base";
		vdd_cx-supply = <&VDD_CX_LEVEL>;
		vdd_gdsc-supply = <&npu_core_gdsc>;
		#clock-cells = <1>;
		#reset-cells = <1>;
	};

	clock_gpucc: qcom,gpucc {
		compatible = "qcom,gpucc-sm8150", "syscon";
		reg = <0x2c90000 0x9000>;
		reg-names = "cc_base";
		vdd_cx-supply = <&VDD_CX_LEVEL>;
		vdd_mx-supply = <&VDD_MX_LEVEL>;
		qcom,gpu_cc_gmu_clk_src-opp-handle = <&gmu>;
		#clock-cells = <1>;
		#reset-cells = <1>;
	};

	clock_scc: qcom,scc@2b10000 {
		compatible = "qcom,scc-sm8150";
		reg = <0x2b10000 0x30000>;
		vdd_scc_cx-supply = <&pm8150_l8_level>;
		#clock-cells = <1>;
		status = "disabled";
	};

	cpucc_debug: syscon@182a0018 {
		compatible = "syscon";
		reg = <0x182a0018 0x4>;
	};

	mccc_debug: syscon@90b0000 {
		compatible = "syscon";
		reg = <0x90b0000 0x1000>;
	};

	clock_debugcc: qcom,cc-debug {
		compatible = "qcom,debugcc-sm8150";
		qcom,gcc = <&clock_gcc>;
		qcom,videocc = <&clock_videocc>;
		qcom,camcc = <&clock_camcc>;
		qcom,dispcc = <&clock_dispcc>;
		qcom,npucc = <&clock_npucc>;
		qcom,gpucc = <&clock_gpucc>;
		qcom,cpucc = <&cpucc_debug>;
		qcom,mccc = <&mccc_debug>;
		clock-names = "xo_clk_src";
		clocks = <&clock_rpmh RPMH_CXO_CLK>;
		#clock-cells = <1>;
	};

	cpufreq_hw: qcom,cpufreq-hw {
		compatible = "qcom,cpufreq-hw";
		reg = <0x18323000 0x1400>, <0x18325800 0x1400>,
		<0x18327800 0x1400>;
		reg-names = "freq-domain0", "freq-domain1",
		"freq-domain2";

		clocks = <&clock_rpmh RPMH_CXO_CLK>, <&clock_gcc GPLL0>;
		clock-names = "xo", "alternate";
		qcom,no-accumulative-counter;
		#freq-domain-cells = <2>;
	};

	qcom_clk_led: qcom_clk_led {
		compatible = "qcom,clk-led-pwm";
		qcom,label = "led_clk_gp2";
		clocks = <&clock_gcc GCC_GP2_CLK>;
		clock-names = "core";
		assigned-clocks = <&clock_gcc GCC_GP2_CLK>;
		assigned-clock-rates = <80000>;
		qcom,max_duty = <53>;
		pinctrl-names = "active", "sleep";
		pinctrl-0 = <&qcom_clk_led_gp2_active>;
		pinctrl-1 = <&qcom_clk_led_gp2_sleep>;
		status = "disabled";
	};

	spmi_bus: qcom,spmi@c440000 {
		compatible = "qcom,spmi-pmic-arb";
		reg = <0xc440000 0x1100>,
		      <0xc600000 0x2000000>,
		      <0xe600000 0x100000>,
		      <0xe700000 0xa0000>,
		      <0xc40a000 0x26000>;
		reg-names = "core", "chnls", "obsrvr", "intr", "cnfg";
		interrupt-names = "periph_irq";
		interrupts = <GIC_SPI 481 IRQ_TYPE_LEVEL_HIGH>;
		qcom,ee = <0>;
		qcom,channel = <0>;
		#address-cells = <2>;
		#size-cells = <0>;
		interrupt-controller;
		#interrupt-cells = <4>;
		cell-index = <0>;
	};

	spmi_debug_bus: qcom,spmi-debug@6b22000 {
		compatible = "qcom,spmi-pmic-arb-debug";
		reg = <0x6b22000 0x60>, <0x7820a8 4>;
		reg-names = "core", "fuse";
		clocks = <&clock_aop QDSS_CLK>;
		clock-names = "core_clk";
		qcom,fuse-disable-bit = <24>;
		#address-cells = <2>;
		#size-cells = <0>;
		status = "disabled";

		qcom,pm8150-debug@0 {
			compatible = "qcom,spmi-pmic";
			reg = <0x0 SPMI_USID>;
			#address-cells = <2>;
			#size-cells = <0>;
			qcom,can-sleep;
		};

		qcom,pm8150-debug@1 {
			compatible = "qcom,spmi-pmic";
			reg = <0x1 SPMI_USID>;
			#address-cells = <2>;
			#size-cells = <0>;
			qcom,can-sleep;
		};

		qcom,pm8150b-debug@2 {
			compatible = "qcom,spmi-pmic";
			reg = <0x2 SPMI_USID>;
			#address-cells = <2>;
			#size-cells = <0>;
			qcom,can-sleep;
		};

		qcom,pm8150b-debug@3 {
			compatible = "qcom,spmi-pmic";
			reg = <0x3 SPMI_USID>;
			#address-cells = <2>;
			#size-cells = <0>;
			qcom,can-sleep;
		};

		qcom,pm8150l-debug@4 {
			compatible = "qcom,spmi-pmic";
			reg = <0x4 SPMI_USID>;
			#address-cells = <2>;
			#size-cells = <0>;
			qcom,can-sleep;
		};

		qcom,pm8150l-debug@5 {
			compatible = "qcom,spmi-pmic";
			reg = <0x5 SPMI_USID>;
			#address-cells = <2>;
			#size-cells = <0>;
			qcom,can-sleep;
		};
	};

	mc_virt: interconnect@0 {
		compatible = "qcom,sm8150-mc_virt";
		#interconnect-cells = <1>;
		qcom,bcm-voter-names = "hlos", "disp";
		qcom,bcm-voters = <&apps_bcm_voter>, <&disp_bcm_voter>;
	};

	camnoc_virt: interconnect@1 {
		compatible = "qcom,sm8150-camnoc_virt";
		#interconnect-cells = <1>;
		qcom,bcm-voter-names = "hlos";
		qcom,bcm-voters = <&apps_bcm_voter>;
	};

	compute_noc: interconnect@2 {
		compatible = "qcom,sm8150-compute_noc";
		#interconnect-cells = <1>;
		qcom,bcm-voter-names = "hlos";
		qcom,bcm-voters = <&apps_bcm_voter>;
	};

	config_noc: interconnect@1500000 {
		reg = <0x1500000 0x7400>;
		compatible = "qcom,sm8150-config_noc";
		#interconnect-cells = <1>;
		qcom,bcm-voter-names = "hlos";
		qcom,bcm-voters = <&apps_bcm_voter>;
	};

	system_noc: interconnect@1620000 {
		reg = <0x1620000 0x19400>;
		compatible = "qcom,sm8150-system_noc";
		#interconnect-cells = <1>;
		qcom,bcm-voter-names = "hlos";
		qcom,bcm-voters = <&apps_bcm_voter>;
	};

	aggre1_noc: interconnect@16e0000 {
		reg = <0x016e0000 0xD080>;
		compatible = "qcom,sm8150-aggre1_noc";
		#interconnect-cells = <1>;
		qcom,bcm-voter-names = "hlos";
		qcom,bcm-voters = <&apps_bcm_voter>;
		clocks = <&clock_gcc GCC_AGGRE_UFS_PHY_AXI_CLK>,
		<&clock_gcc GCC_AGGRE_USB3_PRIM_AXI_CLK>,
		<&clock_gcc GCC_AGGRE_USB3_SEC_AXI_CLK>;
	};

	aggre2_noc: interconnect@1700000 {
		reg = <0x1700000 0x3B100>;
		compatible = "qcom,sm8150-aggre2_noc";
		#interconnect-cells = <1>;
		qcom,bcm-voter-names = "hlos";
		qcom,bcm-voters = <&apps_bcm_voter>;
		clocks = <&clock_rpmh RPMH_IPA_CLK>;
	};

	mmss_noc: interconnect@1740000 {
		reg = <0x1740000 0x1C100>;
		compatible = "qcom,sm8150-mmss_noc";
		#interconnect-cells = <1>;
		qcom,bcm-voter-names = "hlos", "disp";
		qcom,bcm-voters = <&apps_bcm_voter>, <&disp_bcm_voter>;
	};

	dc_noc: interconnect@14e0000 {
		reg = <0x14e0000 0x3200>;
		compatible = "qcom,sm8150-dc_noc";
		#interconnect-cells = <1>;
		qcom,bcm-voter-names = "hlos";
		qcom,bcm-voters = <&apps_bcm_voter>;
	};

	gem_noc: interconnect@9680000 {
		reg = <0x9680000 0x3E200>;
		compatible = "qcom,sm8150-gem_noc";
		#interconnect-cells = <1>;
		qcom,bcm-voter-names = "hlos", "disp";
		qcom,bcm-voters = <&apps_bcm_voter>, <&disp_bcm_voter>;
	};

	osm_l3: interconnect@18321000 {
		reg = <0x18321000 0x1400>;
		compatible = "qcom,sm8150-osm-l3";
		clocks = <&clock_rpmh RPMH_CXO_CLK>, <&clock_gcc GPLL0>;
		clock-names = "xo", "alternate";
		#interconnect-cells = <1>;
	};

	eud: qcom,msm-eud@88e0000 {
		compatible = "qcom,msm-eud";
		interrupt-names = "eud_irq";
		interrupts = <GIC_SPI 492 IRQ_TYPE_LEVEL_HIGH>;
		reg = <0x88e0000 0x2000>;
		reg-names = "eud_base";
		status = "ok";
	};

	pil_modem: qcom,mss@4080000 {
		compatible = "qcom,pil-tz-generic";
		reg = <0x4080000 0x100>;

		clocks = <&clock_rpmh RPMH_CXO_CLK>;
		clock-names = "xo";
		qcom,proxy-clock-names = "xo";

		vdd_cx-supply = <&VDD_CX_LEVEL>;
		qcom,vdd_cx-uV-uA = <RPMH_REGULATOR_LEVEL_TURBO 100000>;
		vdd_mss-supply = <&pm8150_s1_level>;
		qcom,vdd_mss-uV-uA = <RPMH_REGULATOR_LEVEL_TURBO 100000>;
		qcom,proxy-reg-names = "vdd_cx", "vdd_mss";

		qcom,firmware-name = "modem";
		memory-region = <&pil_modem_mem>;
		qcom,proxy-timeout-ms = <10000>;
		qcom,sysmon-id = <0>;
		qcom,minidump-id = <3>;
		qcom,aux-minidump-ids = <4>;
		qcom,ssctl-instance-id = <0x12>;
		qcom,pas-id = <4>;
		qcom,smem-id = <421>;
		qcom,signal-aop;
		qcom,complete-ramdump;

		/* Inputs from mss */
		interrupts-extended = <&intc GIC_SPI 266 IRQ_TYPE_EDGE_RISING>,
				<&modem_smp2p_in 0 IRQ_TYPE_LEVEL_HIGH>,
				<&modem_smp2p_in 2 IRQ_TYPE_LEVEL_HIGH>,
				<&modem_smp2p_in 1 IRQ_TYPE_LEVEL_HIGH>,
				<&modem_smp2p_in 3 IRQ_TYPE_LEVEL_HIGH>,
				<&modem_smp2p_in 7 IRQ_TYPE_LEVEL_HIGH>;

		interrupt-names = "qcom,wdog",
				"qcom,err-fatal",
				"qcom,proxy-unvote",
				"qcom,err-ready",
				"qcom,stop-ack",
				"qcom,shutdown-ack";

		/* Outputs to mss */
		qcom,smem-states = <&modem_smp2p_out 0>;
		qcom,smem-state-names = "qcom,force-stop";

		mboxes = <&qmp_aop 0>;
		mbox-names = "mss-pil";
	};

	qcom,lpass@17300000 {
		compatible = "qcom,pil-tz-generic";
		reg = <0x17300000 0x00100>;

		vdd_cx-supply = <&VDD_CX_LEVEL>;
		qcom,vdd_cx-uV-uA = <RPMH_REGULATOR_LEVEL_TURBO 0>;
		qcom,proxy-reg-names = "vdd_cx";

		clocks = <&clock_rpmh RPMH_CXO_CLK>;
		clock-names = "xo";
		qcom,proxy-clock-names = "xo";

		qcom,pas-id = <1>;
		qcom,proxy-timeout-ms = <10000>;
		qcom,smem-id = <423>;
		qcom,sysmon-id = <1>;
		qcom,ssctl-instance-id = <0x14>;
		qcom,firmware-name = "adsp";
		memory-region = <&pil_adsp_mem>;
		qcom,signal-aop;
		qcom,complete-ramdump;

		/* Inputs from lpass */
		interrupts-extended = <&intc GIC_SPI 162 IRQ_TYPE_EDGE_RISING>,
				<&adsp_smp2p_in 0 IRQ_TYPE_LEVEL_HIGH>,
				<&adsp_smp2p_in 2 IRQ_TYPE_LEVEL_HIGH>,
				<&adsp_smp2p_in 1 IRQ_TYPE_LEVEL_HIGH>,
				<&adsp_smp2p_in 3 IRQ_TYPE_LEVEL_HIGH>,
				<&adsp_smp2p_in 7 IRQ_TYPE_LEVEL_HIGH>;

		interrupt-names = "qcom,wdog",
				"qcom,err-fatal",
				"qcom,proxy-unvote",
				"qcom,err-ready",
				"qcom,stop-ack",
				"qcom,shutdown-ack";

		/* Outputs to lpass */
		qcom,smem-states = <&adsp_smp2p_out 0>;
		qcom,smem-state-names = "qcom,force-stop";

		mboxes = <&qmp_aop 0>;
		mbox-names = "adsp-pil";
	};

	pil_ssc: qcom,ssc@5c00000 {
		compatible = "qcom,pil-tz-generic";
		reg = <0x5c00000 0x4000>;

		vdd_cx-supply = <&pm8150_l8_level>;
		qcom,vdd_cx-uV-uA = <RPMH_REGULATOR_LEVEL_TURBO 0>;
		vdd_mx-supply = <&pm8150_l4_level>;
		qcom,vdd_mx-uV-uA = <RPMH_REGULATOR_LEVEL_TURBO 0>;

		qcom,proxy-reg-names = "vdd_cx", "vdd_mx";
		qcom,keep-proxy-regs-on;

		clocks = <&clock_rpmh RPMH_CXO_CLK>;
		clock-names = "xo";
		qcom,proxy-clock-names = "xo";

		qcom,pas-id = <12>;
		qcom,proxy-timeout-ms = <10000>;
		qcom,smem-id = <424>;
		qcom,sysmon-id = <3>;
		qcom,ssctl-instance-id = <0x16>;
		qcom,firmware-name = "slpi";
		status = "ok";
		memory-region = <&pil_slpi_mem>;
		qcom,signal-aop;
		qcom,complete-ramdump;

		/* Inputs from ssc */
		interrupts-extended = <&intc GIC_SPI 494 IRQ_TYPE_EDGE_RISING>,
				<&dsps_smp2p_in 0 IRQ_TYPE_LEVEL_HIGH>,
				<&dsps_smp2p_in 2 IRQ_TYPE_LEVEL_HIGH>,
				<&dsps_smp2p_in 1 IRQ_TYPE_LEVEL_HIGH>,
				<&dsps_smp2p_in 3 IRQ_TYPE_LEVEL_HIGH>;

		interrupt-names = "qcom,wdog",
				"qcom,err-fatal",
				"qcom,proxy-unvote",
				"qcom,err-ready",
				"qcom,stop-ack";

		/* Outputs to ssc */
		qcom,smem-states = <&dsps_smp2p_out 0>;
		qcom,smem-state-names = "qcom,force-stop";

		mboxes = <&qmp_aop 0>;
		mbox-names = "slpi-pil";
	};

	qcom,spss@1880000 {
		compatible = "qcom,pil-tz-generic";
		reg = <0x188101c 0x4>,
		      <0x1881024 0x4>,
		      <0x1881028 0x4>,
		      <0x188103c 0x4>,
		      <0x1882014 0x4>;
		reg-names = "sp2soc_irq_status", "sp2soc_irq_clr",
			    "sp2soc_irq_mask", "rmb_err", "rmb_err_spare2";
		interrupts = <GIC_SPI 352 IRQ_TYPE_EDGE_RISING>;

		vdd_cx-supply = <&VDD_CX_LEVEL>;
		qcom,proxy-reg-names = "vdd_cx";
		qcom,vdd_cx-uV-uA = <RPMH_REGULATOR_LEVEL_TURBO 100000>;
		vdd_mx-supply = <&VDD_MX_LEVEL>;
		vdd_mx-uV = <RPMH_REGULATOR_LEVEL_TURBO 100000>;

		clocks = <&clock_rpmh RPMH_CXO_CLK>;
		clock-names = "xo";
		qcom,proxy-clock-names = "xo";
		qcom,pil-generic-irq-handler;
		status = "ok";
		qcom,signal-aop;
		qcom,complete-ramdump;

		qcom,pas-id = <14>;
		qcom,proxy-timeout-ms = <10000>;
		qcom,firmware-name = "spss";
		memory-region = <&pil_spss_mem>;
		qcom,spss-scsr-bits = <24 25>;

		mboxes = <&qmp_aop 0>;
		mbox-names = "spss-pil";
	};

	wdog: qcom,wdt@17c10000{
		compatible = "qcom,msm-watchdog";
		reg = <0x17c10000 0x1000>;
		reg-names = "wdt-base";
		interrupts = <GIC_SPI 0 IRQ_TYPE_LEVEL_HIGH>,
			<GIC_SPI 1 IRQ_TYPE_LEVEL_HIGH>;
		qcom,scandump-sizes = <0x10100 0x10100 0x10100 0x10100
		0x18100 0x18100 0x18100 0x18100>;
	};

	qcom,npu@9800000 {
		compatible = "qcom,pil-tz-generic";
		reg = <0x9800000 0x800000>;

		status = "ok";
		qcom,pas-id = <23>;
		qcom,firmware-name = "npu";

		memory-region = <&pil_npu_mem>;
	};

	qcom,turing@8300000 {
		compatible = "qcom,pil-tz-generic";
		reg = <0x8300000 0x100000>;

		vdd_cx-supply = <&VDD_CX_LEVEL>;
		qcom,proxy-reg-names = "vdd_cx";
		qcom,vdd_cx-uV-uA = <RPMH_REGULATOR_LEVEL_TURBO 100000>;

		clocks = <&clock_rpmh RPMH_CXO_CLK>;
		clock-names = "xo";
		qcom,proxy-clock-names = "xo";

		qcom,pas-id = <18>;
		qcom,proxy-timeout-ms = <10000>;
		qcom,smem-id = <601>;
		qcom,sysmon-id = <7>;
		qcom,ssctl-instance-id = <0x17>;
		qcom,firmware-name = "cdsp";
		memory-region = <&pil_cdsp_mem>;
		qcom,signal-aop;
		qcom,complete-ramdump;

		interconnect-names = "pil-cdsp";
		interconnects = <&compute_noc MASTER_NPU &compute_noc SLAVE_CDSP_MEM_NOC>;

		/* Inputs from turing */
		interrupts-extended = <&intc GIC_SPI 578 IRQ_TYPE_EDGE_RISING>,
				<&cdsp_smp2p_in 0 IRQ_TYPE_LEVEL_HIGH>,
				<&cdsp_smp2p_in 2 IRQ_TYPE_LEVEL_HIGH>,
				<&cdsp_smp2p_in 1 IRQ_TYPE_LEVEL_HIGH>,
				<&cdsp_smp2p_in 3 IRQ_TYPE_LEVEL_HIGH>,
				<&cdsp_smp2p_in 7 IRQ_TYPE_LEVEL_HIGH>;

		interrupt-names = "qcom,wdog",
				"qcom,err-fatal",
				"qcom,proxy-unvote",
				"qcom,err-ready",
				"qcom,stop-ack",
				"qcom,shutdown-ack";

		/* Outputs to turing */
		qcom,smem-states = <&cdsp_smp2p_out 0>;
		qcom,smem-state-names = "qcom,force-stop";

		mboxes = <&qmp_aop 0>;
		mbox-names = "cdsp-pil";
	};

	qcom,venus@aae0000 {
		compatible = "qcom,pil-tz-generic";
		reg = <0xaae0000 0x4000>;

		vdd-supply = <&mvsc_gdsc>;
		qcom,proxy-reg-names = "vdd";
		qcom,complete-ramdump;

		clocks = <&clock_videocc VIDEO_CC_XO_CLK>,
			<&clock_videocc VIDEO_CC_MVSC_CORE_CLK>,
			<&clock_videocc VIDEO_CC_IRIS_AHB_CLK>;
		clock-names = "xo", "core", "ahb";
		qcom,proxy-clock-names = "xo",  "core", "ahb";

		qcom,core-freq = <200000000>;
		qcom,ahb-freq = <200000000>;

		qcom,pas-id = <9>;
		interconnect-names = "pil-venus";
		interconnects = <&mmss_noc MASTER_VIDEO_P0
				&mc_virt SLAVE_EBI1>;
		qcom,proxy-timeout-ms = <100>;
		qcom,firmware-name = "venus";
		memory-region = <&pil_video_mem>;
	};

	kryo-erp {
		compatible = "arm,arm64-kryo-cpu-erp";
		interrupts = <GIC_PPI 6 IRQ_TYPE_LEVEL_HIGH>,
			     <GIC_PPI 7 IRQ_TYPE_LEVEL_HIGH>,
			     <GIC_SPI 34 IRQ_TYPE_LEVEL_HIGH>,
			     <GIC_SPI 35 IRQ_TYPE_LEVEL_HIGH>;

		interrupt-names = "l1-l2-faultirq",
				  "l1-l2-errirq",
				  "l3-scu-errirq",
				  "l3-scu-faultirq";
	};

	qcom,chd_sliver {
		compatible = "qcom,core-hang-detect";
		label = "silver";
		qcom,threshold-arr = <0x18000058 0x18010058
		0x18020058 0x18030058>;
		qcom,config-arr = <0x18000060 0x18010060
		0x18020060 0x18030060>;
	};

	qcom,chd_gold {
		compatible = "qcom,core-hang-detect";
		label = "gold";
		qcom,threshold-arr = <0x18040058 0x18050058
		0x18060058 0x18070058>;
		qcom,config-arr = <0x18040060 0x18050060
		0x18060060 0x18070060>;
	};

	qcom,ghd {
		compatible = "qcom,gladiator-hang-detect-v3";
		qcom,threshold-arr = <0x17e0041C>;
		qcom,config-reg = <0x17e00434>;
	};

	cache-controller@9200000 {
		compatible = "qcom,sm8150-llcc";
		reg = <0x9200000 0x200000>, <0x9600000 0x50000>;
		reg-names = "llcc_base", "llcc_broadcast_base";
		cap-based-alloc-and-pwr-collapse;
		clocks = <&clock_aop QDSS_CLK>;
		clock-names = "qdss_clk";
	};

	ssc_sensors: qcom,msm-ssc-sensors {
		compatible = "qcom,msm-ssc-sensors";
		status = "ok";
		qcom,firmware-name = "slpi";
	};

	qtee_shmbridge {
		compatible = "qcom,tee-shared-memory-bridge";
	};

	qcom,memshare {
		compatible = "qcom,memshare";

		qcom,client_1 {
			compatible = "qcom,memshare-peripheral";
			qcom,peripheral-size = <0x0>;
			qcom,client-id = <0>;
			qcom,allocate-boot-time;
			label = "modem";
		};

		qcom,client_2 {
			compatible = "qcom,memshare-peripheral";
			qcom,peripheral-size = <0x0>;
			qcom,client-id = <2>;
			label = "modem";
		};

		mem_client_3_size: qcom,client_3 {
			compatible = "qcom,memshare-peripheral";
			qcom,peripheral-size = <0x500000>;
			qcom,client-id = <1>;
			qcom,allocate-boot-time;
			label = "modem";
		};
	};

	qcom,sps {
		compatible = "qcom,msm-sps-4k";
		qcom,pipe-attr-ee;
	};

	tcsr_mutex_block: syscon@1f40000 {
		compatible = "syscon";
		reg = <0x1f40000 0x20000>;
	};

	tcsr_mutex: hwlock@1f40000 {
		compatible = "qcom,tcsr-mutex";
		syscon = <&tcsr_mutex_block 0 0x1000>;
		#hwlock-cells = <1>;
	};

	smem: qcom,smem@8600000 {
		compatible = "qcom,smem";
		memory-region = <&smem_region>;
		hwlocks = <&tcsr_mutex 3>;
	};

	apcs: syscon@17c0000c {
		compatible = "syscon";
		reg = <0x17c0000c 0x4>;
	};

	ufs_ice: ufsice@1d90000 {
		compatible = "qcom,ice";
		reg = <0x1d90000 0x8000>;
		qcom,enable-ice-clk;
		clock-names = "ufs_core_clk", "bus_clk",
			"iface_clk", "ice_core_clk";
		clocks = <&clock_gcc GCC_UFS_PHY_AXI_CLK>,
			<&clock_gcc GCC_UFS_MEM_CLKREF_CLK>,
			<&clock_gcc GCC_UFS_PHY_AHB_CLK>,
			<&clock_gcc GCC_UFS_PHY_ICE_CORE_CLK>;
		qcom,op-freq-hz = <0>, <0>, <0>, <300000000>;
		vdd-hba-supply = <&ufs_phy_gdsc>;
		qcom,bus-vector-names = "MIN",
			"MAX";
		qcom,instance-type = "ufs";
	};

	ufsphy_mem: ufsphy_mem@1d87000 {
		reg = <0x1d87000 0xda8>; /* PHY regs */
		reg-names = "phy_mem", "ufs_ice";
		#phy-cells = <0>;

		lanes-per-direction = <2>;

		clock-names = "ref_clk_src",
			"ref_clk",
			"ref_aux_clk";
		clocks = <&clock_rpmh RPMH_CXO_CLK>,
			<&clock_gcc GCC_UFS_MEM_CLKREF_CLK>,
			<&clock_gcc GCC_UFS_PHY_PHY_AUX_CLK>;

		resets = <&ufshc_mem 0>;
		status = "disabled";
	};

	ufshc_mem: ufshc@1d84000 {
		compatible = "qcom,ufshc";
		reg = <0x1d84000 0x2500>, <0x1d90000 0x8000>;
		reg-names = "ufs_mem", "ufs_ice";
		interrupts = <GIC_SPI 265 IRQ_TYPE_LEVEL_HIGH>;
		phys = <&ufsphy_mem>;
		phy-names = "ufsphy";
		#reset-cells = <1>;

		lanes-per-direction = <2>;
		dev-ref-clk-freq = <0>; /* 19.2 MHz */

		clock-names =
			"core_clk",
			"bus_aggr_clk",
			"iface_clk",
			"core_clk_unipro",
			"core_clk_ice",
			"ref_clk",
			"tx_lane0_sync_clk",
			"rx_lane0_sync_clk",
			"rx_lane1_sync_clk";
		clocks =
			<&clock_gcc GCC_UFS_PHY_AXI_CLK>,
			<&clock_gcc GCC_AGGRE_UFS_PHY_AXI_CLK>,
			<&clock_gcc GCC_UFS_PHY_AHB_CLK>,
			<&clock_gcc GCC_UFS_PHY_UNIPRO_CORE_CLK>,
			<&clock_gcc GCC_UFS_PHY_ICE_CORE_CLK>,
			<&clock_rpmh RPMH_CXO_CLK>,
			<&clock_gcc GCC_UFS_PHY_TX_SYMBOL_0_CLK>,
			<&clock_gcc GCC_UFS_PHY_RX_SYMBOL_0_CLK>,
			<&clock_gcc GCC_UFS_PHY_RX_SYMBOL_1_CLK>;
		freq-table-hz =
			<37500000 300000000>,
			<0 0>,
			<0 0>,
			<37500000 300000000>,
			<37500000 300000000>,
			<0 0>,
			<0 0>,
			<0 0>,
			<0 0>;

		interconnects = <&aggre1_noc MASTER_UFS_MEM &mc_virt SLAVE_EBI1>,
			<&gem_noc MASTER_APPSS_PROC &config_noc SLAVE_UFS_MEM_CFG>;
		interconnect-names = "ufs-ddr", "cpu-ufs";

		qcom,ufs-bus-bw,name = "ufshc_mem";
		qcom,ufs-bus-bw,num-cases = <26>;
		qcom,ufs-bus-bw,num-paths = <2>;
		qcom,ufs-bus-bw,vectors-KBps =
		/*
		 * During HS G3 UFS runs at nominal voltage corner, vote
		 * higher bandwidth to push other buses in the data path
		 * to run at nominal to achieve max throughput.
		 * 4GBps pushes BIMC to run at nominal.
		 * 200MBps pushes CNOC to run at nominal.
		 * Vote for half of this bandwidth for HS G3 1-lane.
		 * For max bandwidth, vote high enough to push the buses
		 * to run in turbo voltage corner.
		 */
		<0 0>, <0 0>,          /* No vote */
		<922 0>, <1000 0>,     /* PWM G1 */
		<1844 0>, <1000 0>,    /* PWM G2 */
		<3688 0>, <1000 0>,    /* PWM G3 */
		<7376 0>, <1000 0>,    /* PWM G4 */
		<1844 0>, <1000 0>,    /* PWM G1 L2 */
		<3688 0>, <1000 0>,    /* PWM G2 L2 */
		<7376 0>, <1000 0>,    /* PWM G3 L2 */
		<14752 0>, <1000 0>,   /* PWM G4 L2 */
		<127796 0>, <1000 0>,  /* HS G1 RA */
		<255591 0>, <1000 0>,  /* HS G2 RA */
		<2097152 0>, <102400 0>,  /* HS G3 RA */
		<4194304 0>, <204800 0>,  /* HS G4 RA */
		<255591 0>, <1000 0>,  /* HS G1 RA L2 */
		<511181 0>, <1000 0>,  /* HS G2 RA L2 */
		<4194304 0>, <204800 0>, /* HS G3 RA L2 */
		<8388608 0>, <409600 0>, /* HS G4 RA L2 */
		<149422 0>, <1000 0>,  /* HS G1 RB */
		<298189 0>, <1000 0>,  /* HS G2 RB */
		<2097152 0>, <102400 0>,  /* HS G3 RB */
		<4194304 0>, <204800 0>,  /* HS G4 RB */
		<298189 0>, <1000 0>,  /* HS G1 RB L2 */
		<596378 0>, <1000 0>,  /* HS G2 RB L2 */
		/* As UFS working in HS G3 RB L2 mode, aggregated
		 * bandwidth (AB) should take care of providing
		 * optimum throughput requested. However, as tested,
		 * in order to scale up CNOC clock, instantaneous
		 * bindwidth (IB) needs to be given a proper value too.
		 */
		<4194304 0>, <204800 409600>, /* HS G3 RB L2 */
		<8388608 0>, <409600 409600>, /* HS G4 RB L2 */
		<7643136 0>, <307200 0>; /* Max. bandwidth */

		qcom,bus-vector-names = "MIN",
		"PWM_G1_L1", "PWM_G2_L1", "PWM_G3_L1", "PWM_G4_L1",
		"PWM_G1_L2", "PWM_G2_L2", "PWM_G3_L2", "PWM_G4_L2",
		"HS_RA_G1_L1", "HS_RA_G2_L1", "HS_RA_G3_L1", "HS_RA_G4_L1",
		"HS_RA_G1_L2", "HS_RA_G2_L2", "HS_RA_G3_L2", "HS_RA_G4_L2",
		"HS_RB_G1_L1", "HS_RB_G2_L1", "HS_RB_G3_L1", "HS_RB_G4_L1",
		"HS_RB_G1_L2", "HS_RB_G2_L2", "HS_RB_G3_L2", "HS_RB_G4_L2",
		"MAX";

		reset-gpios = <&tlmm 175 GPIO_ACTIVE_LOW>;

		resets = <&clock_gcc GCC_UFS_PHY_BCR>;
		reset-names = "core_reset";

		status = "disabled";
		qos0 {
			mask = <0x0f>;
			vote = <44>;
		};


		qos1 {
			mask = <0xf0>;
			vote = <44>;
		};
	};

	qcom,msm-cdsp-loader {
		compatible = "qcom,cdsp-loader";
		qcom,proc-img-to-load = "cdsp";
	};

	qcom,msm-adsprpc-mem {
		compatible = "qcom,msm-adsprpc-mem-region";
		memory-region = <&adsp_mem>;
	};

	msm_fastrpc: qcom,msm_fastrpc {
		compatible = "qcom,msm-fastrpc-compute";
		qcom,fastrpc-adsp-audio-pdr;
		qcom,rpc-latency-us = <235>;
		qcom,qos-cores = <0 1 2 3>;

		qcom,msm_fastrpc_compute_cb1 {
			compatible = "qcom,msm-fastrpc-compute-cb";
			label = "cdsprpc-smd";
			iommus = <&apps_smmu 0x1401 0x2040>,
				 <&apps_smmu 0x1421 0x0>,
				 <&apps_smmu 0x2001 0x420>,
				 <&apps_smmu 0x2041 0x0>;
			qcom,iommu-dma-addr-pool = <0x80000000 0x78000000>;
			qcom,iommu-faults = "stall-disable", "HUPCF";
			dma-coherent-hint-cached;
		};

		qcom,msm_fastrpc_compute_cb4 {
			compatible = "qcom,msm-fastrpc-compute-cb";
			label = "cdsprpc-smd";
			iommus = <&apps_smmu 0x4 0x3440>,
				 <&apps_smmu 0x24 0x3400>;
			qcom,iommu-dma-addr-pool = <0x80000000 0x78000000>;
			qcom,iommu-faults = "stall-disable", "HUPCF";
			dma-coherent-hint-cached;
		};

		qcom,msm_fastrpc_compute_cb5 {
			compatible = "qcom,msm-fastrpc-compute-cb";
			label = "cdsprpc-smd";
			iommus = <&apps_smmu 0x5 0x3440>,
				 <&apps_smmu 0x25 0x3400>;
			qcom,iommu-dma-addr-pool = <0x80000000 0x78000000>;
			qcom,iommu-faults = "stall-disable", "HUPCF";
			dma-coherent-hint-cached;
		};

		qcom,msm_fastrpc_compute_cb6 {
			compatible = "qcom,msm-fastrpc-compute-cb";
			label = "cdsprpc-smd";
			iommus = <&apps_smmu 0x6 0x3460>;
			qcom,iommu-dma-addr-pool = <0x80000000 0x78000000>;
			qcom,iommu-faults = "stall-disable", "HUPCF";
			dma-coherent-hint-cached;
		};

		qcom,msm_fastrpc_compute_cb7 {
			compatible = "qcom,msm-fastrpc-compute-cb";
			label = "cdsprpc-smd";
			iommus = <&apps_smmu 0x7 0x3460>;
			qcom,iommu-dma-addr-pool = <0x80000000 0x78000000>;
			qcom,iommu-faults = "stall-disable", "HUPCF";
			dma-coherent-hint-cached;
		};

		qcom,msm_fastrpc_compute_cb8 {
			compatible = "qcom,msm-fastrpc-compute-cb";
			label = "cdsprpc-smd";
			iommus = <&apps_smmu 0x8 0x3460>;
			qcom,iommu-dma-addr-pool = <0x80000000 0x78000000>;
			qcom,iommu-faults = "stall-disable", "HUPCF";
			dma-coherent-hint-cached;
		};

		qcom,msm_fastrpc_compute_cb2 {
			compatible = "qcom,msm-fastrpc-compute-cb";
			label = "cdsprpc-smd";
			iommus = <&apps_smmu 0x2 0x3440>,
				 <&apps_smmu 0x22 0x3400>;
			qcom,iommu-dma-addr-pool = <0x80000000 0x78000000>;
			qcom,iommu-faults = "stall-disable", "HUPCF";
			dma-coherent-hint-cached;
		};

		qcom,msm_fastrpc_compute_cb3 {
			compatible = "qcom,msm-fastrpc-compute-cb";
			label = "cdsprpc-smd";
			iommus = <&apps_smmu 0x3 0x3440>,
				 <&apps_smmu 0x1423 0x0>,
				 <&apps_smmu 0x2023 0x0>;
			qcom,iommu-dma-addr-pool = <0x80000000 0x78000000>;
			qcom,iommu-faults = "stall-disable", "HUPCF";
			dma-coherent-hint-cached;
		};

		qcom,msm_fastrpc_compute_cb9 {
			compatible = "qcom,msm-fastrpc-compute-cb";
			label = "cdsprpc-smd";
			qcom,secure-context-bank;
			iommus = <&apps_smmu 0x9 0x3460>;
			qcom,iommu-dma-addr-pool = <0x60000000 0x78000000>;
			qcom,iommu-faults = "stall-disable", "HUPCF";
			qcom,iommu-vmid = <0xA>;	/* VMID_CP_PIXEL */
			dma-coherent-hint-cached;
		};

		qcom,msm_fastrpc_compute_cb10 {
			compatible = "qcom,msm-fastrpc-compute-cb";
			label = "adsprpc-smd";
			iommus = <&apps_smmu 0x1b23 0x0>;
			qcom,iommu-dma-addr-pool = <0x80000000 0x78000000>;
			qcom,iommu-faults = "stall-disable", "HUPCF";
			dma-coherent-hint-cached;
		};

		qcom,msm_fastrpc_compute_cb11 {
			compatible = "qcom,msm-fastrpc-compute-cb";
			label = "adsprpc-smd";
			iommus = <&apps_smmu 0x1b24 0x0>;
			qcom,iommu-dma-addr-pool = <0x80000000 0x78000000>;
			qcom,iommu-faults = "stall-disable", "HUPCF";
			dma-coherent-hint-cached;
		};

		qcom,msm_fastrpc_compute_cb12 {
			compatible = "qcom,msm-fastrpc-compute-cb";
			label = "adsprpc-smd";
			iommus = <&apps_smmu 0x1b25 0x0>;
			qcom,iommu-dma-addr-pool = <0x80000000 0x78000000>;
			qcom,iommu-faults = "stall-disable", "HUPCF";
			dma-coherent-hint-cached;
		};

#if 0
		qcom,msm_fastrpc_compute_cb13 {
			compatible = "qcom,msm-fastrpc-compute-cb";
			label = "sdsprpc-smd";
			iommus = <&apps_smmu 0x5a1 0x0>;
			qcom,iommu-dma-addr-pool = <0x80000000 0x78000000>;
			qcom,iommu-faults = "stall-disable", "HUPCF";
			dma-coherent-hint-cached;
		};

		qcom,msm_fastrpc_compute_cb14 {
			compatible = "qcom,msm-fastrpc-compute-cb";
			label = "sdsprpc-smd";
			iommus = <&apps_smmu 0x5a2 0x0>;
			qcom,iommu-dma-addr-pool = <0x80000000 0x78000000>;
			qcom,iommu-faults = "stall-disable", "HUPCF";
			dma-coherent-hint-cached;
		};

		qcom,msm_fastrpc_compute_cb15 {
			compatible = "qcom,msm-fastrpc-compute-cb";
			label = "sdsprpc-smd";
			iommus = <&apps_smmu 0x5a3 0x0>;
			qcom,iommu-dma-addr-pool = <0x80000000 0x78000000>;
			qcom,iommu-faults = "stall-disable", "HUPCF";
			shared-cb = <4>;
			dma-coherent-hint-cached;
		};
#endif
	};

	sdhc_2: sdhci@8804000 {
		compatible = "qcom,sdhci-msm-v5";
		reg = <0x8804000 0x1000>;
		reg-names = "hc_mem";

		interrupts = <GIC_SPI 204 IRQ_TYPE_LEVEL_HIGH>, <GIC_SPI 222 IRQ_TYPE_LEVEL_HIGH>;
		interrupt-names = "hc_irq", "pwr_irq";

		qcom,bus-width = <4>;
		qcom,large-address-bus;

		interconnects = <&aggre2_noc MASTER_SDCC_2 &mc_virt SLAVE_EBI1>,
			<&gem_noc MASTER_APPSS_PROC &config_noc SLAVE_SDCC_2>;
		interconnect-names = "sdhc-ddr","cpu-sdhc";

		qcom,msm-bus,name = "sdhc2";
		qcom,msm-bus,num-cases = <8>;
		qcom,msm-bus,num-paths = <2>;
		qcom,msm-bus,vectors-KBps =
			/* No vote */
			<0 0>, <0 0>,
			/* 400 KB/s*/
			<1046 1600>, <1600 1600>,
			/* 20 MB/s */
			<52286 80000>, <80000 80000>,
			/* 25 MB/s */
			<65360 100000>, <100000 100000>,
			/* 50 MB/s */
			<130718 200000>, <133320 133320>,
			/* 100 MB/s */
			<261438 200000>, <150000 150000>,
			/* 200 MB/s */
			<261438 400000>, <300000 300000>,
			/* Max. bandwidth */
			<1338562 4096000>, <1338562 4096000>;
		qcom,bus-bw-vectors-bps = <0 400000 20000000 25000000 50000000
			100750000 200000000 4294967295>;

		qcom,restore-after-cx-collapse;

		qcom,clk-rates = <400000 20000000 25000000
					50000000 100000000 201500000>;
		qcom,bus-speed-mode = "SDR12", "SDR25", "SDR50", "DDR50",
				      "SDR104";

		qcom,devfreq,freq-table = <50000000 201500000>;
		clocks = <&clock_gcc GCC_SDCC2_AHB_CLK>,
			<&clock_gcc GCC_SDCC2_APPS_CLK>;
		clock-names = "iface", "core";

		status = "disabled";
		qos0 {
			mask = <0x3f>;
			vote = <44>;
		};

		qos1 {
			mask = <0xc0>;
			vote = <44>;
		};
	};

	apps_rsc: rsc@18200000 {
		compatible = "qcom,rpmh-rsc";
		label = "apps_rsc";
		reg = <0x18200000 0x10000>,
		      <0x18210000 0x10000>,
		      <0x18220000 0x10000>;
		reg-names = "drv-0", "drv-1", "drv-2";
		interrupts = <GIC_SPI 3 IRQ_TYPE_LEVEL_HIGH>,
			     <GIC_SPI 4 IRQ_TYPE_LEVEL_HIGH>,
			     <GIC_SPI 5 IRQ_TYPE_LEVEL_HIGH>;
		qcom,tcs-offset = <0xd00>;
		qcom,drv-id = <2>;
		qcom,tcs-config = <ACTIVE_TCS  2>,
				  <SLEEP_TCS   3>,
				  <WAKE_TCS    3>,
				  <CONTROL_TCS 1>;

		apps_bcm_voter: bcm_voter {
			compatible = "qcom,bcm-voter";
		};

		system_pm {
			compatible = "qcom,system-pm";
		};

		clock_rpmh: qcom,rpmhclk {
			compatible = "qcom,sm8150-rpmh-clk";
			#clock-cells = <1>;
		};
	};

	disp_rsc: rsc@af20000 {
		compatible = "qcom,rpmh-rsc";
		label = "display_rsc";
		reg = <0xaf20000 0x10000>;
		reg-names = "drv-0";
		interrupts = <GIC_SPI 129 IRQ_TYPE_LEVEL_HIGH>;
		qcom,tcs-offset = <0x1c00>;
		qcom,drv-id = <0>;
		qcom,tcs-config = <SLEEP_TCS   1>,
				  <WAKE_TCS    1>,
				  <ACTIVE_TCS  2>,
				  <CONTROL_TCS 0>;

		disp_bcm_voter: bcm_voter {
			compatible = "qcom,bcm-voter";
			qcom,tcs-wait = <QCOM_ICC_TAG_AMC>;
		};

		sde_rsc_rpmh {
			compatible = "qcom,sde-rsc-rpmh";
			cell-index = <0>;
		};
	};

	apcs_glb: mailbox@17c00000 {
		compatible = "qcom,sm8150-apss-shared";
		reg = <0x17c00000 0x1000>;

		#mbox-cells = <1>;
	};

	sp_scsr: mailbox@188501c {
		compatible = "qcom,sm8150-spcs-global";
		reg = <0x188501c 0x4>;

		#mbox-cells = <1>;
	};

	sp_scsr_block: syscon@1880000 {
		compatible = "syscon";
		reg = <0x1880000 0x10000>;
	};

	intsp: qcom,qsee_irq {
		compatible = "qcom,sm8150-qsee-irq";

		syscon = <&sp_scsr_block>;
		interrupts = <GIC_SPI 348 IRQ_TYPE_LEVEL_HIGH>,
			     <GIC_SPI 349 IRQ_TYPE_LEVEL_HIGH>;

		interrupt-names = "sp_ipc0",
				  "sp_ipc1";

		interrupt-controller;
		#interrupt-cells = <3>;
	};

	qcom,qsee_irq_bridge {
		compatible = "qcom,qsee-ipc-irq-bridge";

		qcom,qsee-ipc-irq-spss {
			qcom,dev-name = "qsee_ipc_irq_spss";
			label = "spss";
			interrupt-parent = <&intsp>;
			interrupts = <GIC_PPI 0 IRQ_TYPE_LEVEL_HIGH>;
		};
	};

	qcom,glink {
		compatible = "qcom,glink";
		#address-cells = <1>;
		#size-cells = <1>;
		ranges;

		glink_modem: modem {
			qcom,remote-pid = <1>;
			transport = "smem";
			mboxes = <&apcs_glb 12>;
			mbox-names = "mpss_smem";
			interrupts = <GIC_SPI 449 IRQ_TYPE_EDGE_RISING>;

			label = "modem";
			qcom,glink-label = "mpss";

			qcom,modem_qrtr {
				qcom,glink-channels = "IPCRTR";
				qcom,low-latency;
				qcom,intents = <0x800  5
						0x2000 3
						0x4400 2>;
			};

			qcom,msm_fastrpc_rpmsg {
				compatible = "qcom,msm-fastrpc-rpmsg";
				qcom,glink-channels = "fastrpcglink-apps-dsp";
				qcom,intents = <0x64 64>;
			};

			qcom,modem_ds {
				qcom,glink-channels = "DS";
				qcom,intents = <0x4000 0x2>;
			};

			qcom,modem_glink_ssr {
				qcom,glink-channels = "glink_ssr";
				qcom,notify-edges = <&glink_adsp>,
						    <&glink_slpi>,
						    <&glink_cdsp>,
						    <&glink_spss>;
			};
		};

		glink_adsp: adsp {
			qcom,remote-pid = <2>;
			transport = "smem";
			mboxes = <&apcs_glb 8>;
			mbox-names = "adsp_smem";
			interrupts = <GIC_SPI 156 IRQ_TYPE_EDGE_RISING>;

			label = "adsp";
			qcom,glink-label = "lpass";
			cpu-affinity = <1 2>;

			qcom,adsp_qrtr {
				qcom,glink-channels = "IPCRTR";
				qcom,intents = <0x800  5
						0x2000 3
						0x4400 2>;
			};

			qcom,apr_tal_rpmsg {
				qcom,glink-channels = "apr_audio_svc";
				qcom,intents = <0x200 20>;
			};

			qcom,gpr {
				compatible = "qcom,gpr";
				qcom,glink-channels = "to_apps";
				qcom,intents = <0x200 20>;
				reg = <GPR_DOMAIN_ADSP>;
				gecko_core {
					compatible = "qcom,gecko_core";
					reg = <GPR_SVC_ADSP_CORE>;
				};
				audio-pkt {
					compatible = "qcom,audio-pkt";
					qcom,audiopkt-ch-name = "apr_audio_svc";
					reg = <GPR_SVC_MAX>;
				};
				q6prm {
					compatible = "qcom,q6prm";
					reg = <GPR_SVC_ASM>;
				};
			};

			qcom,msm_fastrpc_rpmsg {
				compatible = "qcom,msm-fastrpc-rpmsg";
				qcom,glink-channels = "fastrpcglink-apps-dsp";
				qcom,intents = <0x64 64>;
			};

			qcom,adsp_glink_ssr {
				qcom,glink-channels = "glink_ssr";
				qcom,notify-edges = <&glink_modem>,
						    <&glink_slpi>,
						    <&glink_cdsp>;
			};
		};

		glink_slpi: dsps {
			qcom,remote-pid = <3>;
			transport = "smem";
			mboxes = <&apcs_glb 24>;
			mbox-names = "dsps_smem";
			interrupts = <GIC_SPI 170 IRQ_TYPE_EDGE_RISING>;

			label = "slpi";
			qcom,glink-label = "dsps";

			qcom,slpi_qrtr {
				qcom,glink-channels = "IPCRTR";
				qcom,low-latency;
				qcom,intents = <0x800  5
						0x2000 3
						0x4400 2>;
			};

			qcom,msm_fastrpc_rpmsg {
				compatible = "qcom,msm-fastrpc-rpmsg";
				qcom,glink-channels = "fastrpcglink-apps-dsp";
				qcom,intents = <0x64 64>;
			};

			qcom,slpi_glink_ssr {
				qcom,glink-channels = "glink_ssr";
				qcom,notify-edges = <&glink_modem>,
						    <&glink_adsp>,
						    <&glink_cdsp>;
			};
		};

		glink_cdsp: cdsp {
			qcom,remote-pid = <5>;
			transport = "smem";
			mboxes = <&apcs_glb 4>;
			mbox-names = "cdsp_smem";
			interrupts = <GIC_SPI 574 IRQ_TYPE_EDGE_RISING>;

			label = "cdsp";
			qcom,glink-label = "cdsp";

			qcom,cdsp_qrtr {
				qcom,glink-channels = "IPCRTR";
				qcom,intents = <0x800  5
						0x2000 3
						0x4400 2>;
			};

			qcom,msm_fastrpc_rpmsg {
				compatible = "qcom,msm-fastrpc-rpmsg";
				qcom,glink-channels = "fastrpcglink-apps-dsp";
				qcom,intents = <0x64 64>;
			};

			qcom,msm_cdsprm_rpmsg {
				compatible = "qcom,msm-cdsprm-rpmsg";
				qcom,glink-channels = "cdsprmglink-apps-dsp";
				qcom,intents = <0x20 12>;

				qcom,cdsp-cdsp-l3-gov {
					compatible = "qcom,cdsp-l3";
					qcom,target-dev = <&cdsp_cdsp_l3_lat>;
				};

				msm_cdsp_rm: qcom,msm_cdsp_rm {
					compatible = "qcom,msm-cdsp-rm";
					qcom,qos-latency-us = <44>;
					qcom,qos-maxhold-ms = <20>;
					qcom,compute-cx-limit-en;
					qcom,compute-priority-mode = <2>;
					#cooling-cells = <2>;
				};

				msm_hvx_rm: qcom,msm_hvx_rm {
					compatible = "qcom,msm-hvx-rm";
					#cooling-cells = <2>;
				};
			};

			qcom,cdsp_glink_ssr {
				qcom,glink-channels = "glink_ssr";
				qcom,notify-edges = <&glink_modem>,
						    <&glink_adsp>,
						    <&glink_slpi>;
			};
		};

		glink_spss: spss {
			qcom,remote-pid = <8>;
			transport = "spss";
			mboxes = <&sp_scsr 0>;
			mbox-names = "spss_spss";
			interrupt-parent = <&intsp>;
			interrupts = <GIC_SPI 0 IRQ_TYPE_LEVEL_HIGH>;

			reg = <0x1885008 0x8>,
			      <0x1885010 0x4>;
			reg-names = "qcom,spss-addr",
				    "qcom,spss-size";

			label = "spss";
			qcom,glink-label = "spss";

			qcom,spss_glink_ssr {
				qcom,glink-channels = "glink_ssr";
				qcom,notify-edges = <&glink_modem>;
			};
		};

		glink_spi_xprt_wdsp: wdsp {
			transport = "spi";
			tx-descriptors = <0x12000 0x12004>;
			rx-descriptors = <0x1200c 0x12010>;

			label = "wdsp";
			qcom,glink-label = "wdsp";

			qcom,wdsp_ctrl {
				qcom,glink-channels = "g_glink_ctrl";
				qcom,intents = <0x400 1>;
			};

			qcom,wdsp_ild {
				qcom,glink-channels =
					"g_glink_persistent_data_ild";
			};

			qcom,wdsp_nild {
				qcom,glink-channels =
					"g_glink_persistent_data_nild";
			};

			qcom,wdsp_data {
				qcom,glink-channels = "g_glink_audio_data";
				qcom,intents = <0x1000 2>;
			};

			qcom,diag_data {
				qcom,glink-channels = "DIAG_DATA";
				qcom,intents = <0x4000 2>;
			};

			qcom,diag_ctrl {
				qcom,glink-channels = "DIAG_CTRL";
				qcom,intents = <0x4000 1>;
			};

			qcom,diag_cmd {
				qcom,glink-channels = "DIAG_CMD";
				qcom,intents = <0x4000 1 >;
			};
		};
	};

	qcom,glinkpkt {
		compatible = "qcom,glinkpkt";

		qcom,glinkpkt-at-mdm0 {
			qcom,glinkpkt-edge = "mpss";
			qcom,glinkpkt-ch-name = "DS";
			qcom,glinkpkt-dev-name = "at_mdm0";
		};

		qcom,glinkpkt-apr-apps2 {
			qcom,glinkpkt-edge = "adsp";
			qcom,glinkpkt-ch-name = "apr_apps2";
			qcom,glinkpkt-dev-name = "apr_apps2";
		};

		qcom,glinkpkt-data40-cntl {
			qcom,glinkpkt-edge = "mpss";
			qcom,glinkpkt-ch-name = "DATA40_CNTL";
			qcom,glinkpkt-dev-name = "smdcntl8";
		};

		qcom,glinkpkt-data1 {
			qcom,glinkpkt-edge = "mpss";
			qcom,glinkpkt-ch-name = "DATA1";
			qcom,glinkpkt-dev-name = "smd7";
		};

		qcom,glinkpkt-data4 {
			qcom,glinkpkt-edge = "mpss";
			qcom,glinkpkt-ch-name = "DATA4";
			qcom,glinkpkt-dev-name = "smd8";
		};

		qcom,glinkpkt-data11 {
			qcom,glinkpkt-edge = "mpss";
			qcom,glinkpkt-ch-name = "DATA11";
			qcom,glinkpkt-dev-name = "smd11";
		};
	};

	qmp_aop: qcom,qmp-aop@c300000 {
		compatible = "qcom,qmp-mbox";
		reg = <0xc300000 0x1000>, <0x17c0000C 0x4>;
		reg-names = "msgram", "irq-reg-base";
		qcom,irq-mask = <0x1>;
		interrupts = <GIC_SPI 389 IRQ_TYPE_EDGE_RISING>;
		mboxes = <&apcs_glb 0>;
		mbox-names = "aop_qmp";
		label = "aop";
		qcom,early-boot;
		priority = <0>;
		mbox-desc-offset = <0x0>;
		#mbox-cells = <1>;
	};

	qmp_npu0: qcom,qmp-npu-low@9818000 {
		compatible = "qcom,qmp-mbox";
		reg = <0x9818000 0x8000>, <0x9901008 0x4>;
		reg-names = "msgram", "irq-reg-base";
		qcom,irq-mask = <0x12>;
		interrupts = <GIC_SPI 369 IRQ_TYPE_EDGE_RISING>;
		mboxes = <&sp_scsr 0>;
		mbox-names = "high_npu_qmp";
		label = "npu_qmp_low";
		priority = <0>;
		mbox-desc-offset = <0x0>;
		#mbox-cells = <1>;
	};

	qmp_npu1: qcom,qmp-npu-high@9818000 {
		compatible = "qcom,qmp-mbox";
		reg = <0x9818000 0x8000>, <0x9901008 0x4>;
		reg-names = "msgram", "irq-reg-base";
		qcom,irq-mask = <0x14>;
		interrupts = <GIC_SPI 370 IRQ_TYPE_EDGE_RISING>;
		mboxes = <&sp_scsr 1>;
		mbox-names = "low_npu_qmp";
		label = "npu_qmp_high";
		priority = <1>;
		mbox-desc-offset = <0x2000>;
		#mbox-cells = <1>;
	};

	qcom,smp2p_sleepstate {
		compatible = "qcom,smp2p-sleepstate";
		qcom,smem-states = <&sleepstate_smp2p_out 0>;
		interrupt-parent = <&sleepstate_smp2p_in>;
		interrupts = <0 IRQ_TYPE_LEVEL_HIGH>;
		interrupt-names = "smp2p-sleepstate-in";
	};

	qcom_seecom: qseecom@87900000 {
		compatible = "qcom,qseecom";
		reg = <0x87900000 0x3E00000>;
		reg-names = "secapp-region";
		memory-region = <&qseecom_mem>;
		qcom,hlos-num-ce-hw-instances = <1>;
		qcom,hlos-ce-hw-instance = <0>;
		qcom,qsee-ce-hw-instance = <0>;
		qcom,disk-encrypt-pipe-pair = <2>;
		qcom,support-fde;
		qcom,no-clock-support;
		qcom,fde-key-size;
		qcom,appsbl-qseecom-support;
		qcom,commonlib64-loaded-by-uefi;
		qcom,qsee-reentrancy-support = <2>;
	};

	qcom_smcinvoke: smcinvoke@87900000 {
		compatible = "qcom,smcinvoke";
		reg = <0x87900000 0x3E00000>;
		reg-names = "secapp-region";
		qcom,support-legacy_smc;
	};

	qcom_rng: qrng@793000 {
		compatible = "qcom,msm-rng";
		reg = <0x793000 0x1000>;
		qcom,msm-rng-iface-clk;
		qcom,no-qrng-config;
		interconnect-names = "data_path";
		interconnects = <&gem_noc MASTER_APPSS_PROC &config_noc SLAVE_PRNG>;
		clocks = <&clock_gcc GCC_PRNG_AHB_CLK>;
		clock-names = "km_clk_src";
	};

	qcom_cedev: qcedev@1de0000 {
		compatible = "qcom,qcedev";
		reg = <0x1de0000 0x20000>,
			<0x1dc4000 0x24000>;
		reg-names = "crypto-base","crypto-bam-base";
		interrupts = <GIC_SPI 272 IRQ_TYPE_LEVEL_HIGH>;
		qcom,bam-pipe-pair = <3>;
		qcom,ce-hw-instance = <0>;
		qcom,ce-device = <0>;
		qcom,ce-hw-shared;
		qcom,bam-ee = <0>;
		interconnect-names = "data_path";
		interconnects = <&aggre2_noc MASTER_CRYPTO &mc_virt SLAVE_EBI1>;
		qcom,smmu-s1-enable;
		qcom,no-clock-support;
		iommus = <&apps_smmu 0x0506 0x0011>,
			 <&apps_smmu 0x0516 0x0011>;
		qcom,iommu-dma = "atomic";

		qcom_cedev_ns_cb {
			compatible = "qcom,qcedev,context-bank";
			label = "ns_context";
			iommus = <&apps_smmu 0x512 0>;
			qcom,iommu-dma-addr-pool = <0x60000000 0x40000000>;
		};

		qcom_cedev_s_cb {
			compatible = "qcom,qcedev,context-bank";
			label = "secure_context";
			iommus = <&apps_smmu 0x513 0>;
			qcom,iommu-vmid = <0x9>; /* VMID_CP_BITSTREAM */
			qcom,iommu-dma-addr-pool = <0xa0000000 0x40000000>;
			qcom,secure-context-bank;
		};
	};

	qcom_msmhdcp: qcom,msm_hdcp {
		compatible = "qcom,msm-hdcp";
	};

	qcom_crypto: qcrypto@1de0000 {
		compatible = "qcom,qcrypto";
		reg = <0x1de0000 0x20000>,
			 <0x1dc4000 0x24000>;
		reg-names = "crypto-base","crypto-bam-base";
		interrupts = <GIC_SPI 272 IRQ_TYPE_LEVEL_HIGH>;
		qcom,bam-pipe-pair = <2>;
		qcom,ce-hw-instance = <0>;
		qcom,ce-device = <0>;
		qcom,bam-ee = <0>;
		qcom,ce-hw-shared;
		qcom,clk-mgmt-sus-res;
		interconnect-names = "data_path";
		interconnects = <&aggre2_noc MASTER_CRYPTO &mc_virt SLAVE_EBI1>;
		qcom,use-sw-aes-cbc-ecb-ctr-algo;
		qcom,use-sw-aes-xts-algo;
		qcom,use-sw-aes-ccm-algo;
		qcom,use-sw-ahash-algo;
		qcom,use-sw-aead-algo;
		qcom,use-sw-hmac-algo;
		qcom,smmu-s1-enable;
		qcom,no-clock-support;
		iommus = <&apps_smmu 0x0504 0x0011>,
			 <&apps_smmu 0x0514 0x0011>;
		qcom,iommu-dma = "atomic";
	};

	qcom_tzlog: tz-log@146bf720 {
		compatible = "qcom,tz-log";
		reg = <0x146bf720 0x3000>;
		qcom,hyplog-enabled;
		hyplog-address-offset = <0x410>;
		hyplog-size-offset = <0x414>;
	};

	dcc: dcc_v2@10a2000 {
		compatible = "qcom,dcc-v2";
		reg = <0x10a2000 0x1000>,
		      <0x10ad000 0x3000>;
		reg-names = "dcc-base", "dcc-ram-base";

		dcc-ram-offset = <0x5000>;

		qcom,curr-link-list = <3>;
		qcom,link-list = <DCC_READ 0x18220d14 3 0>,
				 <DCC_READ 0x18220d30 4 0>,
				 <DCC_READ 0x18220d44 4 0>,
				 <DCC_READ 0x18220d58 4 0>,
				 <DCC_READ 0x18220fb4 3 0>,
				 <DCC_READ 0x18220fd0 4 0>,
				 <DCC_READ 0x18220fe4 4 0>,
				 <DCC_READ 0x18220ff8 4 0>,
				 <DCC_READ 0x18220d04 1 0>,
				 <DCC_READ 0x18220d00 1 0>,
				 <DCC_READ 0x18000024 1 0>,
				 <DCC_READ 0x18000040 3 0>,
				 <DCC_READ 0x18010024 1 0>,
				 <DCC_READ 0x18010040 3 0>,
				 <DCC_READ 0x18020024 1 0>,
				 <DCC_READ 0x18020040 3 0>,
				 <DCC_READ 0x18030024 1 0>,
				 <DCC_READ 0x18030040 3 0>,
				 <DCC_READ 0x18040024 1 0>,
				 <DCC_READ 0x18040040 3 0>,
				 <DCC_READ 0x18050024 1 0>,
				 <DCC_READ 0x18050040 3 0>,
				 <DCC_READ 0x18060024 1 0>,
				 <DCC_READ 0x18060040 3 0>,
				 <DCC_READ 0x18070024 1 0>,
				 <DCC_READ 0x18070040 3 0>,
				 <DCC_READ 0x18080104 1 0>,
				 <DCC_READ 0x18080168 1 0>,
				 <DCC_READ 0x18080198 1 0>,
				 <DCC_READ 0x18080128 1 0>,
				 <DCC_READ 0x18080024 1 0>,
				 <DCC_READ 0x18080040 3 0>,
				 <DCC_READ 0x18200400 3 0>,
				 <DCC_READ 0x0b201020 2 0>,
				 <DCC_READ 0x18101908 1 0>,
				 <DCC_READ 0x18101c18 1 0>,
				 <DCC_READ 0x18390810 1 0>,
				 <DCC_READ 0x18390c50 1 0>,
				 <DCC_READ 0x18390814 1 0>,
				 <DCC_READ 0x18390c54 1 0>,
				 <DCC_READ 0x18390818 1 0>,
				 <DCC_READ 0x18390c58 1 0>,
				 <DCC_READ 0x18393a84 2 0>,
				 <DCC_READ 0x18100908 1 0>,
				 <DCC_READ 0x18100c18 1 0>,
				 <DCC_READ 0x183a0810 1 0>,
				 <DCC_READ 0x183a0c50 1 0>,
				 <DCC_READ 0x183a0814 1 0>,
				 <DCC_READ 0x183a0c54 1 0>,
				 <DCC_READ 0x183a0818 1 0>,
				 <DCC_READ 0x183a0c58 1 0>,
				 <DCC_READ 0x183a3a84 2 0>,
				 <DCC_READ 0x18393500 80 0>,
				 <DCC_READ 0x183a3500 80 0>,
				 <DCC_READ 0x09050008 1 0>,
				 <DCC_READ 0x09050078 1 0>,
				 <DCC_READ 0x09601000 1 0>,
				 <DCC_READ 0x09601004 1 0>,
				 <DCC_READ 0x09602000 1 0>,
				 <DCC_READ 0x09602004 1 0>,
				 <DCC_READ 0x09603000 1 0>,
				 <DCC_READ 0x09603004 1 0>,
				 <DCC_READ 0x09604000 1 0>,
				 <DCC_READ 0x09604004 1 0>,
				 <DCC_READ 0x09605000 1 0>,
				 <DCC_READ 0x09605004 1 0>,
				 <DCC_READ 0x09606000 1 0>,
				 <DCC_READ 0x09606004 1 0>,
				 <DCC_READ 0x09607000 1 0>,
				 <DCC_READ 0x09607004 1 0>,
				 <DCC_READ 0x09608000 1 0>,
				 <DCC_READ 0x09608004 1 0>,
				 <DCC_READ 0x09609000 1 0>,
				 <DCC_READ 0x09609004 1 0>,
				 <DCC_READ 0x0960a000 1 0>,
				 <DCC_READ 0x0960a004 1 0>,
				 <DCC_READ 0x0960b000 1 0>,
				 <DCC_READ 0x0960b004 1 0>,
				 <DCC_READ 0x0960c000 1 0>,
				 <DCC_READ 0x0960c004 1 0>,
				 <DCC_READ 0x0960d000 1 0>,
				 <DCC_READ 0x0960d004 1 0>,
				 <DCC_READ 0x0960e000 1 0>,
				 <DCC_READ 0x0960e004 1 0>,
				 <DCC_READ 0x0960f000 1 0>,
				 <DCC_READ 0x0960f004 1 0>,
				 <DCC_READ 0x09610000 1 0>,
				 <DCC_READ 0x09610004 1 0>,
				 <DCC_READ 0x09611000 1 0>,
				 <DCC_READ 0x09611004 1 0>,
				 <DCC_READ 0x09612000 1 0>,
				 <DCC_READ 0x09612004 1 0>,
				 <DCC_READ 0x09613000 1 0>,
				 <DCC_READ 0x09613004 1 0>,
				 <DCC_READ 0x09614000 1 0>,
				 <DCC_READ 0x09614004 1 0>,
				 <DCC_READ 0x09615000 1 0>,
				 <DCC_READ 0x09615004 1 0>,
				 <DCC_READ 0x09616000 1 0>,
				 <DCC_READ 0x09616004 1 0>,
				 <DCC_READ 0x09617000 1 0>,
				 <DCC_READ 0x09617004 1 0>,
				 <DCC_READ 0x09618000 1 0>,
				 <DCC_READ 0x09618004 1 0>,
				 <DCC_READ 0x09619000 1 0>,
				 <DCC_READ 0x09619004 1 0>,
				 <DCC_READ 0x0961a000 1 0>,
				 <DCC_READ 0x0961a004 1 0>,
				 <DCC_READ 0x0961b000 1 0>,
				 <DCC_READ 0x0961b004 1 0>,
				 <DCC_READ 0x0961c000 1 0>,
				 <DCC_READ 0x0961c004 1 0>,
				 <DCC_READ 0x0961d000 1 0>,
				 <DCC_READ 0x0961d004 1 0>,
				 <DCC_READ 0x0961e000 1 0>,
				 <DCC_READ 0x0961e004 1 0>,
				 <DCC_READ 0x0961f000 1 0>,
				 <DCC_READ 0x0961f004 1 0>,
				 <DCC_WRITE 0x06a0e00c 0x00600007 1>,
				 <DCC_WRITE 0x06a0e01c 0x00136800 1>,
				 <DCC_READ 0x06a0e014 1 1>,
				 <DCC_WRITE 0x06a0e01c 0x00136810 1>,
				 <DCC_READ 0x06a0e014 1 1>,
				 <DCC_WRITE 0x06a0e01c 0x00136820 1>,
				 <DCC_READ 0x06a0e014 1 1>,
				 <DCC_WRITE 0x06a0e01c 0x00136830 1>,
				 <DCC_READ 0x06a0e014 1 1>,
				 <DCC_WRITE 0x06a0e01c 0x00136840 1>,
				 <DCC_READ 0x06a0e014 1 1>,
				 <DCC_WRITE 0x06a0e01c 0x00136850 1>,
				 <DCC_READ 0x06a0e014 1 1>,
				 <DCC_WRITE 0x06a0e01c 0x00136860 1>,
				 <DCC_READ 0x06a0e014 1 1>,
				 <DCC_WRITE 0x06a0e01c 0x00136870 1>,
				 <DCC_READ 0x06a0e014 1 1>,
				 <DCC_WRITE 0x06a0e01c 0x0003e9a0 1>,
				 <DCC_WRITE 0x06a0e01c 0x001368a0 1>,
				 <DCC_READ 0x06a0e014 1 1>,
				 <DCC_WRITE 0x06a0e01c 0x0003c0a0 1>,
				 <DCC_WRITE 0x06a0e01c 0x001368a0 1>,
				 <DCC_READ 0x06a0e014 1 1>,
				 <DCC_WRITE 0x06a0e01c 0x0003d1a0 1>,
				 <DCC_WRITE 0x06a0e01c 0x001368a0 1>,
				 <DCC_READ 0x06a0e014 1 1>,
				 <DCC_WRITE 0x06a0e01c 0x0003d2a0 1>,
				 <DCC_WRITE 0x06a0e01c 0x001368a0 1>,
				 <DCC_READ 0x06a0e014 1 1>,
				 <DCC_WRITE 0x06a0e01c 0x0003d5a0 1>,
				 <DCC_WRITE 0x06a0e01c 0x001368a0 1>,
				 <DCC_READ 0x06a0e014 1 1>,
				 <DCC_WRITE 0x06a0e01c 0x0003d6a0 1>,
				 <DCC_WRITE 0x06a0e01c 0x001368a0 1>,
				 <DCC_READ 0x06a0e014 1 1>,
				 <DCC_WRITE 0x06a0e01c 0x0003e8a0 1>,
				 <DCC_WRITE 0x06a0e01c 0x001368a0 1>,
				 <DCC_READ 0x06a0e014 1 1>,
				 <DCC_WRITE 0x06a0e01c 0x0003eea0 1>,
				 <DCC_WRITE 0x06a0e01c 0x001368a0 1>,
				 <DCC_READ 0x06a0e014 1 1>,
				 <DCC_WRITE 0x06a0e01c 0x0003b1a0 1>,
				 <DCC_WRITE 0x06a0e01c 0x001368a0 1>,
				 <DCC_READ 0x06a0e014 1 1>,
				 <DCC_WRITE 0x06a0e01c 0x0003b2a0 1>,
				 <DCC_WRITE 0x06a0e01c 0x001368a0 1>,
				 <DCC_READ 0x06a0e014 1 1>,
				 <DCC_WRITE 0x06a0e01c 0x0003b5a0 1>,
				 <DCC_WRITE 0x06a0e01c 0x001368a0 1>,
				 <DCC_READ 0x06a0e014 1 1>,
				 <DCC_WRITE 0x06a0e01c 0x0003b6a0 1>,
				 <DCC_WRITE 0x06a0e01c 0x001368a0 1>,
				 <DCC_READ 0x06a0e014 1 1>,
				 <DCC_WRITE 0x06a0e01c 0x0003c2a0 1>,
				 <DCC_WRITE 0x06a0e01c 0x001368a0 1>,
				 <DCC_READ 0x06a0e014 1 1>,
				 <DCC_WRITE 0x06a0e01c 0x0003c5a0 1>,
				 <DCC_WRITE 0x06a0e01c 0x001368a0 1>,
				 <DCC_READ 0x06a0e014 1 1>,
				 <DCC_WRITE 0x06a0e01c 0x0003c6a0 1>,
				 <DCC_WRITE 0x06a0e01c 0x001368a0 1>,
				 <DCC_READ 0x06a0e014 1 1>,
				 <DCC_WRITE 0x06a0e014 0x00020b38 1>,
				 <DCC_WRITE 0x06a0e01c 0x000368b0 1>,
				 <DCC_WRITE 0x06a0e01c 0x00000ba8 1>,
				 <DCC_WRITE 0x06a0e01c 0x0013b6a0 1>,
				 <DCC_WRITE 0x06a0e01c 0x00f1e000 1>,
				 <DCC_WRITE 0x06a0e008 0x00000007 1>,
				 <DCC_READ 0x09067e00 124 0>,
				 <DCC_WRITE 0x090c80f8 0x00000001 1>,
				 <DCC_READ 0x091800c8 1 0>,
				 <DCC_READ 0x09180740 1 0>,
				 <DCC_READ 0x09183740 1 0>,
				 <DCC_READ 0x091900c8 1 0>,
				 <DCC_READ 0x09190740 1 0>,
				 <DCC_READ 0x09193740 1 0>,
				 <DCC_READ 0x09181254 2 0>,
				 <DCC_READ 0x09181624 1 0>,
				 <DCC_READ 0x09181740 1 0>,
				 <DCC_READ 0x09181768 1 0>,
				 <DCC_READ 0x0918182c 1 0>,
				 <DCC_READ 0x09182254 2 0>,
				 <DCC_READ 0x09182624 1 0>,
				 <DCC_READ 0x09182740 1 0>,
				 <DCC_READ 0x09182768 1 0>,
				 <DCC_READ 0x0918282c 1 0>,
				 <DCC_READ 0x09184254 2 0>,
				 <DCC_READ 0x09184624 1 0>,
				 <DCC_READ 0x09184740 1 0>,
				 <DCC_READ 0x09184768 1 0>,
				 <DCC_READ 0x0918482c 1 0>,
				 <DCC_READ 0x09185254 2 0>,
				 <DCC_READ 0x09185624 1 0>,
				 <DCC_READ 0x09185740 1 0>,
				 <DCC_READ 0x09185768 1 0>,
				 <DCC_READ 0x0918582c 1 0>,
				 <DCC_READ 0x09191254 2 0>,
				 <DCC_READ 0x09191624 1 0>,
				 <DCC_READ 0x09191740 1 0>,
				 <DCC_READ 0x09191768 1 0>,
				 <DCC_READ 0x0919182c 1 0>,
				 <DCC_READ 0x09192254 2 0>,
				 <DCC_READ 0x09192624 1 0>,
				 <DCC_READ 0x09192740 1 0>,
				 <DCC_READ 0x09192768 1 0>,
				 <DCC_READ 0x0919282c 1 0>,
				 <DCC_READ 0x09194254 2 0>,
				 <DCC_READ 0x09194624 1 0>,
				 <DCC_READ 0x09194740 1 0>,
				 <DCC_READ 0x09194768 1 0>,
				 <DCC_READ 0x0919482c 1 0>,
				 <DCC_READ 0x09195254 2 0>,
				 <DCC_READ 0x09195624 1 0>,
				 <DCC_READ 0x09195740 1 0>,
				 <DCC_READ 0x09195768 1 0>,
				 <DCC_READ 0x0919582c 1 0>,
				 <DCC_READ 0x09186048 1 0>,
				 <DCC_READ 0x09186054 1 0>,
				 <DCC_READ 0x09186164 1 0>,
				 <DCC_READ 0x09186170 1 0>,
				 <DCC_READ 0x09186410 1 0>,
				 <DCC_READ 0x09186618 4 0>,
				 <DCC_READ 0x091866e0 1 0>,
				 <DCC_READ 0x09186700 2 0>,
				 <DCC_READ 0x09196048 1 0>,
				 <DCC_READ 0x09196054 1 0>,
				 <DCC_READ 0x09196164 1 0>,
				 <DCC_READ 0x09196170 1 0>,
				 <DCC_READ 0x09196410 1 0>,
				 <DCC_READ 0x09196618 4 0>,
				 <DCC_READ 0x091966e0 1 0>,
				 <DCC_READ 0x09196700 2 0>;
	};

	thermal_zones: thermal-zones { };

	slim_aud: slim@171c0000 {
		cell-index = <1>;
		compatible = "qcom,slim-ngd";
		reg = <0x171c0000 0x2c000>,
			<0x17184000 0x2c000>;
		reg-names = "slimbus_physical", "slimbus_bam_physical";
		interrupts = <GIC_SPI 163 IRQ_TYPE_LEVEL_HIGH>, <GIC_SPI 164 IRQ_TYPE_LEVEL_HIGH>;
		interrupt-names = "slimbus_irq", "slimbus_bam_irq";
		qcom,apps-ch-pipes = <0x780000>;
		qcom,ea-pc = <0x2a0>;
		qcom,iommu-s1-bypass;
		iommus = <&apps_smmu 0x1b46 0x8>,
			 <&apps_smmu 0x1b4d 0x2>,
			 <&apps_smmu 0x1b50 0x1>;
		qcom,iommu-dma-addr-pool = <0x40000000 0xc0000000>;
		qcom,iommu-dma = "atomic";
	};

	slim_qca: slim@17240000 {
		status = "ok";
		cell-index = <3>;
		compatible = "qcom,slim-ngd";
		reg = <0x17240000 0x2c000>,
			<0x17204000 0x20000>;
		reg-names = "slimbus_physical", "slimbus_bam_physical";
		interrupts = <GIC_SPI 291 IRQ_TYPE_LEVEL_HIGH>, <GIC_SPI 292 IRQ_TYPE_LEVEL_HIGH>;
		interrupt-names = "slimbus_irq", "slimbus_bam_irq";
		qcom,iommu-s1-bypass;
		iommus = <&apps_smmu 0x1b53 0x0>;
		qcom,iommu-dma-addr-pool = <0x40000000 0xc0000000>;
		qcom,iommu-dma = "atomic";

		/* Slimbus Slave DT for WCN3990 */
		btfmslim_codec: wcn3990 {
			compatible = "qcom,btfmslim_slave";
			elemental-addr = [00 01 20 02 17 02];
			qcom,btfm-slim-ifd = "btfmslim_slave_ifd";
			qcom,btfm-slim-ifd-elemental-addr = [00 00 20 02 17 02];
		};
	};

	gpi_dma0: qcom,gpi-dma@800000 {
		#dma-cells = <5>;
		compatible = "qcom,gpi-dma";
		reg = <0x800000 0x60000>;
		reg-names = "gpi-top";
		interrupts = <GIC_SPI 244 IRQ_TYPE_LEVEL_HIGH>,
			     <GIC_SPI 245 IRQ_TYPE_LEVEL_HIGH>,
				 <GIC_SPI 246 IRQ_TYPE_LEVEL_HIGH>,
				 <GIC_SPI 247 IRQ_TYPE_LEVEL_HIGH>,
			     <GIC_SPI 248 IRQ_TYPE_LEVEL_HIGH>,
				 <GIC_SPI 249 IRQ_TYPE_LEVEL_HIGH>,
				 <GIC_SPI 250 IRQ_TYPE_LEVEL_HIGH>,
				 <GIC_SPI 251 IRQ_TYPE_LEVEL_HIGH>,
			     <GIC_SPI 252 IRQ_TYPE_LEVEL_HIGH>,
				 <GIC_SPI 253 IRQ_TYPE_LEVEL_HIGH>,
				 <GIC_SPI 254 IRQ_TYPE_LEVEL_HIGH>,
				 <GIC_SPI 255 IRQ_TYPE_LEVEL_HIGH>,
			     <GIC_SPI 256 IRQ_TYPE_LEVEL_HIGH>;
		qcom,max-num-gpii = <13>;
		qcom,gpii-mask = <0xfa>;
		qcom,ev-factor = <2>;
		iommus = <&apps_smmu 0x00d6 0x0>;
		qcom,smmu-cfg = <0x1>;
		qcom,iommu-dma-addr-pool = <0x100000 0x100000>;
		status = "ok";
	};

	gpi_dma1: qcom,gpi-dma@a00000 {
		#dma-cells = <5>;
		compatible = "qcom,gpi-dma";
		reg = <0xa00000 0x60000>;
		reg-names = "gpi-top";
		interrupts = <GIC_SPI 279 IRQ_TYPE_LEVEL_HIGH>,
			     <GIC_SPI 280 IRQ_TYPE_LEVEL_HIGH>,
				 <GIC_SPI 281 IRQ_TYPE_LEVEL_HIGH>,
				 <GIC_SPI 282 IRQ_TYPE_LEVEL_HIGH>,
			     <GIC_SPI 283 IRQ_TYPE_LEVEL_HIGH>,
				 <GIC_SPI 284 IRQ_TYPE_LEVEL_HIGH>,
				 <GIC_SPI 293 IRQ_TYPE_LEVEL_HIGH>,
				 <GIC_SPI 294 IRQ_TYPE_LEVEL_HIGH>,
			     <GIC_SPI 295 IRQ_TYPE_LEVEL_HIGH>,
				 <GIC_SPI 296 IRQ_TYPE_LEVEL_HIGH>,
				 <GIC_SPI 297 IRQ_TYPE_LEVEL_HIGH>,
				 <GIC_SPI 298 IRQ_TYPE_LEVEL_HIGH>,
			     <GIC_SPI 299 IRQ_TYPE_LEVEL_HIGH>;
		qcom,max-num-gpii = <13>;
		qcom,gpii-mask = <0xfa>;
		qcom,ev-factor = <2>;
		iommus = <&apps_smmu 0x0616 0x0>;
		qcom,smmu-cfg = <0x1>;
		qcom,iommu-dma-addr-pool = <0x100000 0x100000>;
		status = "ok";
	};

	gpi_dma2: qcom,gpi-dma@c00000 {
		#dma-cells = <5>;
		compatible = "qcom,gpi-dma";
		reg = <0xc00000 0x60000>;
		reg-names = "gpi-top";
		interrupts = <GIC_SPI 588 IRQ_TYPE_LEVEL_HIGH>,
				 <GIC_SPI 589 IRQ_TYPE_LEVEL_HIGH>,
				 <GIC_SPI 590 IRQ_TYPE_LEVEL_HIGH>,
				 <GIC_SPI 591 IRQ_TYPE_LEVEL_HIGH>,
			     <GIC_SPI 592 IRQ_TYPE_LEVEL_HIGH>,
				 <GIC_SPI 593 IRQ_TYPE_LEVEL_HIGH>,
				 <GIC_SPI 594 IRQ_TYPE_LEVEL_HIGH>,
				 <GIC_SPI 595 IRQ_TYPE_LEVEL_HIGH>,
			     <GIC_SPI 596 IRQ_TYPE_LEVEL_HIGH>,
				 <GIC_SPI 597 IRQ_TYPE_LEVEL_HIGH>,
				 <GIC_SPI 598 IRQ_TYPE_LEVEL_HIGH>,
				 <GIC_SPI 599 IRQ_TYPE_LEVEL_HIGH>,
			     <GIC_SPI 600 IRQ_TYPE_LEVEL_HIGH>;
		qcom,max-num-gpii = <13>;
		qcom,gpii-mask = <0xfa>;
		qcom,ev-factor = <2>;
		iommus = <&apps_smmu 0x07b6 0x0>;
		qcom,smmu-cfg = <0x1>;
		qcom,iommu-dma-addr-pool = <0x100000 0x100000>;
		status = "ok";
	};

	qcom,rmtfs_sharedmem@0 {
		compatible = "qcom,sharedmem-uio";
		reg = <0x0 0x300000>;
		reg-names = "rmtfs";
		qcom,client-id = <0x00000001>;
		qcom,guard-memory;
	};

	qcom,msm_gsi {
		compatible = "qcom,msm_gsi";
	};

	qcom,rmnet-ipa {
		compatible = "qcom,rmnet-ipa3";
		qcom,rmnet-ipa-ssr;
		qcom,ipa-advertise-sg-support;
		qcom,ipa-napi-enable;
	};

	ipa_hw: qcom,ipa@1e00000 {
		compatible = "qcom,ipa";
		mboxes = <&qmp_aop 0>;
		reg = <0x1e00000 0x34000>,
		      <0x1e04000 0x28000>;
		reg-names = "ipa-base", "gsi-base";
		interrupts =
			<GIC_SPI 311 IRQ_TYPE_LEVEL_HIGH>,
			<GIC_SPI 432 IRQ_TYPE_LEVEL_HIGH>;
		interrupt-names = "ipa-irq", "gsi-irq";
		qcom,ipa-hw-ver = <15>; /* IPA core version = IPAv4.1 */
		qcom,ipa-hw-mode = <0>;
		qcom,platform-type = <1>; /* MSM platform */
		qcom,ee = <0>;
		qcom,use-ipa-tethering-bridge;
		qcom,modem-cfg-emb-pipe-flt;
		qcom,ipa-wdi2;
		qcom,use-64-bit-dma-mask;
		qcom,arm-smmu;
		qcom,smmu-fast-map;
		qcom,use-ipa-pm;
		clock-names = "core_clk";
		clocks = <&clock_rpmh RPMH_IPA_CLK>;
		qcom,interconnect,num-cases = <5>;
		qcom,interconnect,num-paths = <3>;
		interconnect-names = "ipa_to_ebi1", "ipa_to_imem", "appss_to_ipa";
		interconnects = <&aggre2_noc MASTER_IPA &mc_virt SLAVE_EBI1>,
				<&aggre2_noc MASTER_IPA &system_noc SLAVE_IMEM>,
				<&gem_noc MASTER_APPSS_PROC &config_noc SLAVE_IPA_CFG>;

		/* No vote */
		qcom,no-vote =
				<0 0 0 0 0 0>;

		/* SVS2 */
		qcom,svs2 =
			<80000 600000 80000 350000 40000 40000>;

		/* SVS */
		qcom,svs =
			< 80000 640000 80000 640000 80000 80000>;

		/* NOMINAL */
		qcom,nominal =
			<206000 960000 206000 960000 206000 160000>;

		/* TURBO */
		qcom,turbo =
			<206000 3600000 206000 3600000 206000 300000>;

		qcom,bus-vector-names = "MIN", "SVS2", "SVS", "NOMINAL",
		"TURBO";
		qcom,throughput-threshold = <310 600 1000>;
		qcom,scaling-exceptions = <>;

		/* smp2p information */
		qcom,smp2p_map_ipa_1_out {
			compatible = "qcom,smp2p-map-ipa-1-out";
			qcom,smem-states = <&smp2p_ipa_1_out 0>;
			qcom,smem-state-names = "ipa-smp2p-out";
		};

		qcom,smp2p_map_ipa_1_in {
			compatible = "qcom,smp2p-map-ipa-1-in";
			interrupts-extended = <&smp2p_ipa_1_in 0 IRQ_TYPE_LEVEL_HIGH>;
			interrupt-names = "ipa-smp2p-in";
		};
	};

	ipa_smmu_ap: ipa_smmu_ap {
		compatible = "qcom,ipa-smmu-ap-cb";
		iommus = <&apps_smmu 0x520 0x0>;
		qcom,iommu-dma-addr-pool = <0x20000000 0x40000000>;
		/* modem tables in IMEM */
		qcom,additional-mapping = <0x146BD000 0x146BD000 0x2000>;
		dma-coherent;
		qcom,iommu-dma = "fastmap";
	};

	ipa_smmu_wlan: ipa_smmu_wlan {
		compatible = "qcom,ipa-smmu-wlan-cb";
		iommus = <&apps_smmu 0x521 0x0>;
		/* ipa-uc ram */
		qcom,additional-mapping = <0x1E60000 0x1E60000 0x80000>;
		qcom,iommu-dma = "atomic";
	};

	ipa_smmu_uc: ipa_smmu_uc {
		compatible = "qcom,ipa-smmu-uc-cb";
		iommus = <&apps_smmu 0x522 0x0>;
		qcom,iommu-dma-addr-pool = <0x40400000 0x1FC00000>;
	};

	qcom,ipa_fws {
		compatible = "qcom,pil-tz-generic";
		qcom,pas-id = <0xf>;
		qcom,firmware-name = "ipa_fws";
		qcom,pil-force-shutdown;
		memory-region = <&pil_ipa_fw_mem>;
	};

	aop-msg-client {
		compatible = "qcom,debugfs-qmp-client";
		mboxes = <&qmp_aop 0>;
		mbox-names = "aop";
	};

	qcom,cnss-qca6390@a0000000 {
		compatible = "qcom,cnss-qca6390";
		reg = <0xa0000000 0x10000000>,
		      <0xb0000000 0x10000>;
		reg-names = "smmu_iova_base", "smmu_iova_ipa";
		wlan-en-gpio = <&tlmm 169 0>;
		pinctrl-names = "wlan_en_active", "wlan_en_sleep";
		pinctrl-0 = <&cnss_wlan_en_active>;
		pinctrl-1 = <&cnss_wlan_en_sleep>;
		qcom,wlan-rc-num = <0>;
		qcom,wlan-ramdump-dynamic = <0x400000>;
		qcom,smmu-s1-enable;

		mhi,max-channels = <30>;
		mhi,timeout = <10000>;

		#address-cells = <1>;
		#size-cells = <0>;

		mhi_chan@0 {
			reg = <0>;
			label = "LOOPBACK";
			mhi,num-elements = <32>;
			mhi,event-ring = <1>;
			mhi,chan-dir = <1>;
			mhi,data-type = <0>;
			mhi,doorbell-mode = <2>;
			mhi,ee = <0x14>;
		};

		mhi_chan@1 {
			reg = <1>;
			label = "LOOPBACK";
			mhi,num-elements = <32>;
			mhi,event-ring = <1>;
			mhi,chan-dir = <2>;
			mhi,data-type = <0>;
			mhi,doorbell-mode = <2>;
			mhi,ee = <0x14>;
		};

		mhi_chan@4 {
			reg = <4>;
			label = "DIAG";
			mhi,num-elements = <32>;
			mhi,event-ring = <1>;
			mhi,chan-dir = <1>;
			mhi,data-type = <0>;
			mhi,doorbell-mode = <2>;
			mhi,ee = <0x14>;
		};

		mhi_chan@5 {
			reg = <5>;
			label = "DIAG";
			mhi,num-elements = <32>;
			mhi,event-ring = <1>;
			mhi,chan-dir = <2>;
			mhi,data-type = <0>;
			mhi,doorbell-mode = <2>;
			mhi,ee = <0x14>;
		};

		mhi_chan@20 {
			reg = <20>;
			label = "IPCR";
			mhi,num-elements = <32>;
			mhi,event-ring = <1>;
			mhi,chan-dir = <1>;
			mhi,data-type = <1>;
			mhi,doorbell-mode = <2>;
			mhi,ee = <0x14>;
			mhi,auto-start;
		};

		mhi_chan@21 {
			reg = <21>;
			label = "IPCR";
			mhi,num-elements = <32>;
			mhi,event-ring = <1>;
			mhi,chan-dir = <2>;
			mhi,data-type = <0>;
			mhi,doorbell-mode = <2>;
			mhi,ee = <0x14>;
			mhi,auto-queue;
			mhi,auto-start;
		};

		mhi_event@0 {
			mhi,num-elements = <32>;
			mhi,intmod = <1>;
			mhi,msi = <1>;
			mhi,priority = <1>;
			mhi,brstmode = <2>;
			mhi,data-type = <1>;
		};

		mhi_event@1 {
			mhi,num-elements = <256>;
			mhi,intmod = <1>;
			mhi,msi = <2>;
			mhi,priority = <1>;
			mhi,brstmode = <2>;
		};
	};

	icnss: qcom,icnss@18800000 {
		compatible = "qcom,icnss";
		reg = <0x18800000 0x800000>,
		      <0xb0000000 0x10000>;
		reg-names = "membase", "smmu_iova_ipa";
		iommus = <&apps_smmu 0x0640 0x1>;
		qcom,iommu-dma-addr-pool = <0xa0000000 0x10000000>;
		qcom,iommu-dma = "fastmap";
		qcom,iommu-faults = "stall-disable", "non-fatal";
		qcom,hyp_enabled;
		interrupts = <GIC_SPI 414 IRQ_TYPE_LEVEL_HIGH /* CE0 */ >,
			     <GIC_SPI 415 IRQ_TYPE_LEVEL_HIGH /* CE1 */ >,
			     <GIC_SPI 416 IRQ_TYPE_LEVEL_HIGH /* CE2 */ >,
			     <GIC_SPI 417 IRQ_TYPE_LEVEL_HIGH /* CE3 */ >,
			     <GIC_SPI 418 IRQ_TYPE_LEVEL_HIGH /* CE4 */ >,
			     <GIC_SPI 419 IRQ_TYPE_LEVEL_HIGH /* CE5 */ >,
			     <GIC_SPI 420 IRQ_TYPE_LEVEL_HIGH /* CE6 */ >,
			     <GIC_SPI 421 IRQ_TYPE_LEVEL_HIGH /* CE7 */ >,
			     <GIC_SPI 422 IRQ_TYPE_LEVEL_HIGH /* CE8 */ >,
			     <GIC_SPI 423 IRQ_TYPE_LEVEL_HIGH /* CE9 */ >,
			     <GIC_SPI 424 IRQ_TYPE_LEVEL_HIGH /* CE10 */ >,
			     <GIC_SPI 425 IRQ_TYPE_LEVEL_HIGH /* CE11 */ >;
		qcom,wlan-msa-memory = <0x100000>;
		qcom,wlan-msa-fixed-region = <&pil_wlan_fw_mem>;

		vdd-cx-mx-supply = <&pm8150_l1>;
		vdd-1.8-xo-supply = <&pm8150_l7>;
		vdd-1.3-rfa-supply = <&pm8150l_l2>;
		vdd-3.3-ch0-supply = <&pm8150l_l11>;
		qcom,vdd-cx-mx-config = <752000 752000>;
		qcom,vdd-3.3-ch0-config = <3104000 3312000>;
		qcom,smp2p_map_wlan_1_in {
			interrupts-extended = <&smp2p_wlan_1_in 0 IRQ_TYPE_LEVEL_HIGH>,
					      <&smp2p_wlan_1_in 1 IRQ_TYPE_LEVEL_HIGH>;
			interrupt-names = "qcom,smp2p-force-fatal-error",
					  "qcom,smp2p-early-crash-ind";
		};
	};

	wil6210: qcom,wil6210 {
		compatible = "qcom,wil6210";
		qcom,pcie-parent = <&pcie1>;
		pinctrl-names = "default";
		pinctrl-0 = <&wil6210_refclk3_en_pin>;
		qcom,wigig-en = <&tlmm 131 0>;
		qcom,11ad-bus-bw,name = "wil6210";
		qcom,11ad-bus-bw,num-cases = <2>;
		qcom,11ad-bus-bw,num-paths = <1>;
		qcom,11ad-bus-bw,vectors-KBps =
			<100 512 0 0>,
			<100 512 600000 800000>; /* ~4.6Gbps (MCS12) */
		qcom,use-ext-supply;
		vddio-supply= <&pm8150_s5>;
		qcom,use-ext-clocks;
		clocks = <&clock_rpmh RPMH_RF_CLK3>;
		clock-names = "rf_clk3_clk";
		qcom,smmu-support;
		qcom,smmu-mapping = <0x20000000 0xe0000000>;
		qcom,smmu-s1-en;
		qcom,smmu-fast-map;
		qcom,smmu-coherent;
		qcom,keep-radio-on-during-sleep;
		status = "disabled";
	};

	tspp: msm_tspp@8880000 {
		compatible = "qcom,msm_tspp";
		reg = <0x088a7000 0x200>, /* MSM_TSIF0_PHYS */
		      <0x088a8000 0x200>, /* MSM_TSIF1_PHYS */
		      <0x088a9000 0x1000>, /* MSM_TSPP_PHYS  */
		      <0x08884000 0x23000>; /* MSM_TSPP_BAM_PHYS */
		reg-names = "MSM_TSIF0_PHYS",
			"MSM_TSIF1_PHYS",
			"MSM_TSPP_PHYS",
			"MSM_TSPP_BAM_PHYS";
		interrupts = <GIC_SPI 121 IRQ_TYPE_LEVEL_HIGH>, /* TSIF_TSPP_IRQ */
			<GIC_SPI 119 IRQ_TYPE_LEVEL_HIGH>, /* TSIF0_IRQ */
			<GIC_SPI 120 IRQ_TYPE_LEVEL_HIGH>, /* TSIF1_IRQ */
			<GIC_SPI 122 IRQ_TYPE_LEVEL_HIGH>; /* TSIF_BAM_IRQ */
		interrupt-names = "TSIF_TSPP_IRQ",
			"TSIF0_IRQ",
			"TSIF1_IRQ",
			"TSIF_BAM_IRQ";

		clock-names = "iface_clk", "ref_clk";
		clocks = <&clock_gcc GCC_TSIF_AHB_CLK>,
			<&clock_gcc GCC_TSIF_REF_CLK>;

		interconnect-names = "tsif";
		interconnects = <&aggre2_noc MASTER_TSIF
				&mc_virt SLAVE_EBI1>;
		/* No ICC support yet
		qcom,msm-bus,vectors-KBps =
					<82 512 0 0>, // No vote
					<82 512 12288 24576>;
		*/

		pinctrl-names = "disabled",
			"tsif0-mode1", "tsif0-mode2",
			"tsif1-mode1", "tsif1-mode2",
			"dual-tsif-mode1", "dual-tsif-mode2";

		pinctrl-0 = <>;				/* disabled */
		pinctrl-1 = <&tsif0_signals_active>;	/* tsif0-mode1 */
		pinctrl-2 = <&tsif0_signals_active
			&tsif0_sync_active>;		/* tsif0-mode2 */
		pinctrl-3 = <&tsif1_signals_active>;	/* tsif1-mode1 */
		pinctrl-4 = <&tsif1_signals_active
			&tsif1_sync_active>;		/* tsif1-mode2 */
		pinctrl-5 = <&tsif0_signals_active
			&tsif1_signals_active>;		/* dual-tsif-mode1 */
		pinctrl-6 = <&tsif0_signals_active
			&tsif0_sync_active
			&tsif1_signals_active
			&tsif1_sync_active>;		/* dual-tsif-mode2 */

		memory-region = <&qseecom_mem>;
		qcom,smmu-s1-bypass;
		iommus = <&apps_smmu 0x620 0x00>;
		qcom,iommu-dma-addr-pool = <0x10000000 0x40000000>;
	};

	demux {
		compatible = "qcom,demux";
	};
};

&emac_gdsc {
	status = "ok";
};

&pcie_0_gdsc {
	status = "ok";
};

&pcie_1_gdsc {
	status = "ok";
};

&ufs_phy_gdsc {
	status = "ok";
};

&usb30_prim_gdsc {
	status = "ok";
};

&usb30_sec_gdsc {
	status = "ok";
};

&hlos1_vote_aggre_noc_mmu_audio_tbu_gdsc {
	status = "ok";
};

&hlos1_vote_aggre_noc_mmu_tbu1_gdsc {
	status = "ok";
};

&hlos1_vote_aggre_noc_mmu_tbu2_gdsc {
	status = "ok";
};

&hlos1_vote_aggre_noc_mmu_pcie_tbu_gdsc {
	status = "ok";
};

&hlos1_vote_mmnoc_mmu_tbu_hf0_gdsc {
	status = "ok";
};

&hlos1_vote_mmnoc_mmu_tbu_sf_gdsc {
	status = "ok";
};

&hlos1_vote_mmnoc_mmu_tbu_hf1_gdsc {
	status = "ok";
};

&hlos1_vote_turing_mmu_tbu0_gdsc {
	status = "ok";
};

&hlos1_vote_turing_mmu_tbu1_gdsc {
	status = "ok";
};


&bps_gdsc {
	clock-names = "ahb_clk";
	clocks = <&clock_gcc GCC_CAMERA_AHB_CLK>;
	parent-supply = <&VDD_MMCX_LEVEL>;
	vdd_parent-supply = <&VDD_MMCX_LEVEL>;
	interconnect-names = "bps_gdsc_ahb";
	interconnects = <&gem_noc MASTER_APPSS_PROC
			&config_noc SLAVE_CAMERA_CFG>;
	qcom,support-hw-trigger;
	status = "ok";
};

&ipe_0_gdsc {
	clock-names = "ahb_clk";
	clocks = <&clock_gcc GCC_CAMERA_AHB_CLK>;
	parent-supply = <&VDD_MMCX_LEVEL>;
	vdd_parent-supply = <&VDD_MMCX_LEVEL>;
	interconnect-names = "ipe_0_gdsc_ahb";
	interconnects = <&gem_noc MASTER_APPSS_PROC
			&config_noc SLAVE_CAMERA_CFG>;
	qcom,support-hw-trigger;
	status = "ok";
};

&ipe_1_gdsc {
	clock-names = "ahb_clk";
	clocks = <&clock_gcc GCC_CAMERA_AHB_CLK>;
	parent-supply = <&VDD_MMCX_LEVEL>;
	vdd_parent-supply = <&VDD_MMCX_LEVEL>;
	interconnect-names = "ipe_1_gdsc_ahb";
	interconnects = <&gem_noc MASTER_APPSS_PROC
			&config_noc SLAVE_CAMERA_CFG>;
	qcom,support-hw-trigger;
	status = "ok";
};

&ife_0_gdsc {
	clock-names = "ahb_clk";
	clocks = <&clock_gcc GCC_CAMERA_AHB_CLK>;
	parent-supply = <&VDD_MMCX_LEVEL>;
	vdd_parent-supply = <&VDD_MMCX_LEVEL>;
	interconnect-names = "ife_0_gdsc_ahb";
	interconnects = <&gem_noc MASTER_APPSS_PROC
			&config_noc SLAVE_CAMERA_CFG>;
	status = "ok";
};

&ife_1_gdsc {
	clock-names = "ahb_clk";
	clocks = <&clock_gcc GCC_CAMERA_AHB_CLK>;
	parent-supply = <&VDD_MMCX_LEVEL>;
	vdd_parent-supply = <&VDD_MMCX_LEVEL>;
	interconnect-names = "ife_1_gdsc_ahb";
	interconnects = <&gem_noc MASTER_APPSS_PROC
			&config_noc SLAVE_CAMERA_CFG>;
	status = "ok";
};


&titan_top_gdsc {
	clock-names = "ahb_clk";
	clocks = <&clock_gcc GCC_CAMERA_AHB_CLK>;
	parent-supply = <&VDD_MMCX_LEVEL>;
	vdd_parent-supply = <&VDD_MMCX_LEVEL>;
	interconnect-names = "titan_top_gdsc_ahb";
	interconnects = <&gem_noc MASTER_APPSS_PROC
			&config_noc SLAVE_CAMERA_CFG>;
	status = "ok";
};

&mdss_core_gdsc {
	clock-names = "ahb_clk";
	clocks = <&clock_gcc GCC_DISP_AHB_CLK>;
	parent-supply = <&VDD_MMCX_LEVEL>;
	vdd_parent-supply = <&VDD_MMCX_LEVEL>;
	interconnect-names = "mdss_core_gdsc_ahb";
	interconnects = <&gem_noc MASTER_APPSS_PROC
			&config_noc SLAVE_DISPLAY_CFG>;
	status = "ok";
};

&gpu_cx_gdsc {
	parent-supply = <&VDD_CX_LEVEL>;
	vdd_parent-supply = <&VDD_CX_LEVEL>;
	status = "ok";
};

&gpu_gx_gdsc {
	parent-supply = <&pm8150l_s2_level>;
	vdd_parent-supply = <&pm8150l_s2_level>;
	status = "ok";
};

&mvsc_gdsc {
	clock-names = "ahb_clk";
	clocks = <&clock_gcc GCC_VIDEO_AHB_CLK>;
	parent-supply = <&VDD_MMCX_LEVEL>;
	vdd_parent-supply = <&VDD_MMCX_LEVEL>;
	interconnect-names = "mvsc_gdsc_ahb";
	interconnects = <&gem_noc MASTER_APPSS_PROC
			&config_noc SLAVE_VENUS_CFG>;
	status = "ok";
};


&mvs0_gdsc {
	clock-names = "ahb_clk";
	clocks = <&clock_gcc GCC_VIDEO_AHB_CLK>;
	parent-supply = <&VDD_MMCX_LEVEL>;
	vdd_parent-supply = <&VDD_MMCX_LEVEL>;
	interconnect-names = "mvs0_gdsc_ahb";
	interconnects = <&gem_noc MASTER_APPSS_PROC
			&config_noc SLAVE_VENUS_CFG>;
	qcom,support-hw-trigger;
	status = "ok";
};


&mvs1_gdsc {
	clock-names = "ahb_clk";
	clocks = <&clock_gcc GCC_VIDEO_AHB_CLK>;
	parent-supply = <&VDD_MMCX_LEVEL>;
	vdd_parent-supply = <&VDD_MMCX_LEVEL>;
	interconnect-names = "mvs1_gdsc_ahb";
	interconnects = <&gem_noc MASTER_APPSS_PROC
			&config_noc SLAVE_VENUS_CFG>;
	qcom,support-hw-trigger;
	status = "ok";
};

&npu_core_gdsc {
	clock-names = "ahb_clk";
	clocks = <&clock_gcc GCC_NPU_CFG_AHB_CLK>;
	status = "ok";
};
#include "sm8150-pinctrl.dtsi"
#include "sm8150-slpi-pinctrl.dtsi"
#include "sm8150-regulator.dtsi"
#include "sm8150-ion.dtsi"
#include "sm8150-pcie.dtsi"
#include "sm8150-smp2p.dtsi"
#include "msm-arm-smmu-sm8150.dtsi"
#include "sm8150-qupv3.dtsi"
#include "sm8150-npu.dtsi"
#include "sm8150-pm.dtsi"
#include "sm8150-audio.dtsi"
#include "sm8150-vidc.dtsi"
#include "sm8150-thermal.dtsi"
#include "sm8150-usb.dtsi"
#include "sm8150-gpu.dtsi"
#include "sm8150-mhi.dtsi"
